VERSION "Reviewed Honda profile J35_6AT"

NS_ :

BS_:

BU_: EPS METER PCM UNKNOWN VSA

CM_ BO_ 57 "No saved selected registration; bus presence unproved; direction relative to PCM.";
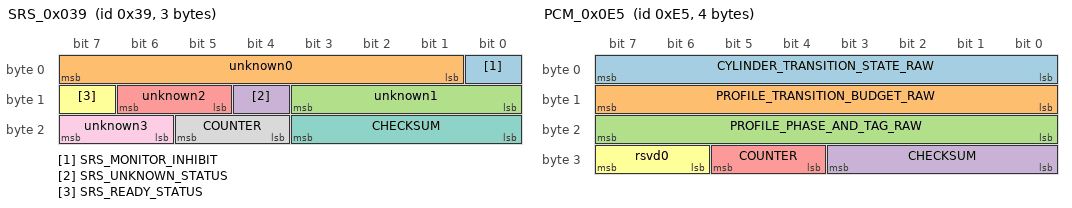
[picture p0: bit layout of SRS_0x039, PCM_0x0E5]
BO_ 57 SRS_0x039: 3 UNKNOWN
 SG_ SRS_MONITOR_INHIBIT : 0|1@1+ (1,0) [0|1] ""  PCM
 SG_ unknown0 : 1|7@1+ (1,0) [0|127] ""  PCM
 SG_ unknown1 : 8|4@1+ (1,0) [0|15] ""  PCM
 SG_ SRS_UNKNOWN_STATUS : 12|1@1+ (1,0) [0|1] ""  PCM
 SG_ unknown2 : 13|2@1+ (1,0) [0|3] ""  PCM
 SG_ SRS_READY_STATUS : 15|1@1+ (1,0) [0|1] ""  PCM
 SG_ CHECKSUM : 16|4@1+ (1,0) [0|15] ""  PCM
 SG_ COUNTER : 20|2@1+ (1,0) [0|3] ""  PCM
 SG_ unknown3 : 22|2@1+ (1,0) [0|3] ""  PCM

CM_ BO_ 145 "No saved selected registration; bus presence unproved; direction relative to PCM. Kinematics codes; X740 HDS associations are reference-only. Physical axes/scales and installed source remain qualified.";
BO_ 145 VSA_0x091: 8 VSA
 SG_ CRYAW2 : 7|10@0+ (1,0) [0|1023] "raw"  PCM
 SG_ AuxiliaryCode : 13|8@0+ (1,0) [0|255] ""  PCM
 SG_ CGLAT2 : 19|10@0+ (1,0) [0|1023] "raw"  PCM
 SG_ unknown0 : 20|2@1+ (1,0) [0|3] ""  PCM
 SG_ CGLON2 : 25|10@0+ (1,0) [0|1023] "raw"  PCM
 SG_ unknown1 : 40|4@1+ (1,0) [0|15] ""  PCM
 SG_ LongitudinalFaultSummary : 44|1@1+ (1,0) [0|1] ""  PCM
 SG_ LateralFaultSummary : 45|1@1+ (1,0) [0|1] ""  PCM
 SG_ MonitorSummary0 : 46|1@1+ (1,0) [0|1] ""  PCM
 SG_ YawFaultSummary : 47|1@1+ (1,0) [0|1] ""  PCM
 SG_ MonitorCondition2 : 48|1@1+ (1,0) [0|1] ""  PCM
 SG_ MonitorSummary1 : 49|1@1+ (1,0) [0|1] ""  PCM
 SG_ unknown2 : 50|2@1+ (1,0) [0|3] ""  PCM
 SG_ LongitudinalFaultCondition : 52|1@1+ (1,0) [0|1] ""  PCM
 SG_ LateralFaultCondition : 53|1@1+ (1,0) [0|1] ""  PCM
 SG_ MonitorCondition0 : 54|1@1+ (1,0) [0|1] ""  PCM
 SG_ YawFaultCondition : 55|1@1+ (1,0) [0|1] ""  PCM
 SG_ CHECKSUM : 56|4@1+ (1,0) [0|15] ""  PCM
 SG_ COUNTER : 60|2@1+ (1,0) [0|3] ""  PCM
 SG_ unknown3 : 62|1@1+ (1,0) [0|1] ""  PCM
 SG_ ScalarNotReady : 63|1@1+ (1,0) [0|1] ""  PCM

CM_ BO_ 229 "TX ACTIVE; DLC4; direction relative to PCM.";
BO_ 229 PCM_0x0E5: 4 PCM
 SG_ CYLINDER_TRANSITION_STATE_RAW : 0|8@1+ (1,0) [0|255] ""  UNKNOWN
 SG_ PROFILE_TRANSITION_BUDGET_RAW : 8|8@1+ (1,0) [0|255] ""  UNKNOWN
 SG_ PROFILE_PHASE_AND_TAG_RAW : 16|8@1+ (1,0) [0|255] ""  UNKNOWN
 SG_ CHECKSUM : 24|4@1+ (1,0) [0|15] ""  UNKNOWN
 SG_ COUNTER : 28|2@1+ (1,0) [0|3] ""  UNKNOWN
 SG_ rsvd0 : 30|2@1+ (1,0) [0|3] ""  UNKNOWN

CM_ BO_ 316 "TX ACTIVE; DLC8; direction relative to PCM. Signed modeled/requested torque codes; Nm scale unresolved.";
BO_ 316 PCM_0x13C: 8 PCM
 SG_ TORQUE_ESTIMATE : 7|16@0- (1,0) [-32768|32767] "raw"  UNKNOWN
 SG_ TORQUE_TARGET : 23|16@0- (1,0) [-32768|32767] "raw"  UNKNOWN
 SG_ APP : 32|8@1+ (0.39215686274509803,0) [0|100] "%"  UNKNOWN
 SG_ TORQUE_STATE : 40|2@1+ (1,0) [0|3] ""  UNKNOWN
 SG_ rsvd0 : 42|2@1+ (1,0) [0|3] ""  UNKNOWN
 SG_ rsvd1 : 44|1@1+ (1,0) [0|1] ""  UNKNOWN
 SG_ FRAME1AA_WINDOW_LATCH : 45|1@1+ (1,0) [0|1] ""  UNKNOWN
 SG_ START_PHASE_LATCH : 46|1@1+ (1,0) [0|1] ""  UNKNOWN
 SG_ DTC_STATUS7_LATCH : 47|1@1+ (1,0) [0|1] ""  UNKNOWN
 SG_ rsvd2 : 48|2@1+ (1,0) [0|3] ""  UNKNOWN
 SG_ CLEPBCC : 50|1@1+ (1,0) [0|1] ""  UNKNOWN
 SG_ CONTROL_GUARD_RAW : 51|1@1+ (1,0) [0|1] ""  UNKNOWN
 SG_ rsvd3 : 52|4@1+ (1,0) [0|15] ""  UNKNOWN
 SG_ CHECKSUM : 56|4@1+ (1,0) [0|15] ""  UNKNOWN
 SG_ COUNTER : 60|2@1+ (1,0) [0|3] ""  UNKNOWN
 SG_ rsvd4 : 62|1@1+ (1,0) [0|1] ""  UNKNOWN
 SG_ FRAME_1AA_INVALID_OR_FALLBACK_ST : 63|1@1+ (1,0) [0|1] ""  UNKNOWN

CM_ BO_ 342 "No saved selected registration; bus presence unproved; direction relative to PCM. Signed BE angle/rate codes; decoder uses -raw*0.1 deg and -raw deg/s. Orientation and installed source remain qualified.";
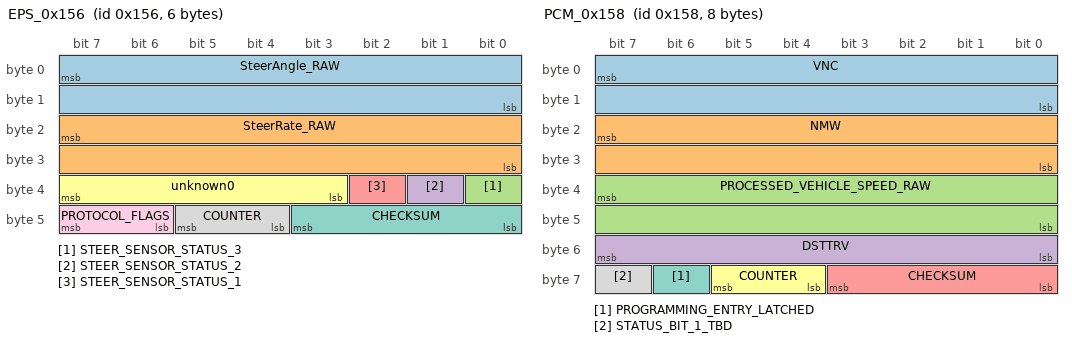
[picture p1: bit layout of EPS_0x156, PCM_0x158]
BO_ 342 EPS_0x156: 6 UNKNOWN
 SG_ SteerAngle_RAW : 7|16@0- (-0.1,0) [-3276.7000000000003|3276.8] "deg"  UNKNOWN
 SG_ SteerRate_RAW : 23|16@0- (-1,0) [-32767|32768] "deg/s"  UNKNOWN
 SG_ STEER_SENSOR_STATUS_3 : 32|1@1+ (1,0) [0|1] ""  UNKNOWN
 SG_ STEER_SENSOR_STATUS_2 : 33|1@1+ (1,0) [0|1] ""  UNKNOWN
 SG_ STEER_SENSOR_STATUS_1 : 34|1@1+ (1,0) [0|1] ""  UNKNOWN
 SG_ unknown0 : 35|5@1+ (1,0) [0|31] ""  UNKNOWN
 SG_ CHECKSUM : 40|4@1+ (1,0) [0|15] ""  UNKNOWN
 SG_ COUNTER : 44|2@1+ (1,0) [0|3] ""  UNKNOWN
 SG_ PROTOCOL_FLAGS : 46|2@1+ (1,0) [0|3] ""  UNKNOWN

CM_ BO_ 344 "TX ACTIVE; DLC8; direction relative to PCM.";
BO_ 344 PCM_0x158: 8 PCM
 SG_ VNC : 7|16@0+ (0.01,0) [0|655.35] ""  UNKNOWN
 SG_ NMW : 23|16@0+ (1,0) [0|65535] "raw"  UNKNOWN
 SG_ PROCESSED_VEHICLE_SPEED_RAW : 39|16@0+ (0.01,0) [0|655.35] ""  UNKNOWN
 SG_ DSTTRV : 48|8@1+ (1,0) [0|255] "raw"  UNKNOWN
 SG_ CHECKSUM : 56|4@1+ (1,0) [0|15] ""  UNKNOWN
 SG_ COUNTER : 60|2@1+ (1,0) [0|3] ""  UNKNOWN
 SG_ PROGRAMMING_ENTRY_LATCHED : 62|1@1+ (1,0) [0|1] ""  UNKNOWN
 SG_ STATUS_BIT_1_TBD : 63|1@1+ (1,0) [0|1] ""  UNKNOWN

CM_ BO_ 380 "TX ACTIVE; DLC8; direction relative to PCM.";
BO_ 380 PCM_0x17C: 8 PCM
 SG_ APP : 0|8@1+ (0.39215686274509803,0) [0|100] "%"  UNKNOWN
 SG_ THROTTLE_ABOVE_IDLE_CODE : 8|8@1+ (0.4,0) [0|102] "deg"  UNKNOWN
 SG_ NE : 23|16@0+ (1,0) [0|65535] "rpm"  UNKNOWN
 SG_ BKSW : 32|1@1+ (1,0) [0|1] ""  UNKNOWN
 SG_ CRUISE_CANCEL_EVENT : 33|1@1+ (1,0) [0|1] ""  UNKNOWN
 SG_ CRUISE_FAULT_SPEED_INHIBIT : 34|1@1+ (1,0) [0|1] ""  UNKNOWN
 SG_ CRUISE_ENGAGED : 35|1@1+ (1,0) [0|1] ""  UNKNOWN
 SG_ WARN : 36|1@1+ (1,0) [0|1] ""  UNKNOWN
 SG_ MILSTAT : 37|1@1+ (1,0) [0|1] ""  UNKNOWN
 SG_ CRPL : 38|1@1+ (1,0) [0|1] ""  UNKNOWN
 SG_ GAS_PEDAL_PRESSED : 39|1@1+ (1,0) [0|1] ""  UNKNOWN
 SG_ rsvd0 : 40|2@1+ (1,0) [0|3] ""  UNKNOWN
 SG_ ACCEL_PEDAL_FAULT : 42|1@1+ (1,0) [0|1] ""  UNKNOWN
 SG_ rsvd1 : 43|5@1+ (1,0) [0|31] ""  UNKNOWN
 SG_ rsvd2 : 48|5@1+ (1,0) [0|31] ""  UNKNOWN
 SG_ BKSWNC : 53|1@1+ (1,0) [0|1] ""  UNKNOWN
 SG_ CRUISE_TRANS_REQUEST_WIRE : 54|2@1+ (1,0) [0|3] ""  UNKNOWN
 SG_ CHECKSUM : 56|4@1+ (1,0) [0|15] ""  UNKNOWN
 SG_ COUNTER : 60|2@1+ (1,0) [0|3] ""  UNKNOWN
 SG_ rsvd3 : 62|1@1+ (1,0) [0|1] ""  UNKNOWN
 SG_ DTC_GROUP_WARNING_REQUESTED : 63|1@1+ (1,0) [0|1] ""  UNKNOWN

CM_ BO_ 392 "TX ACTIVE; DLC6; direction relative to PCM.";
BO_ 392 PCM_0x188: 6 PCM
 SG_ SHIFT_CONTROL_CODE_A_RAW : 0|4@1+ (1,0) [0|15] ""  UNKNOWN
 SG_ TRANSMISSION_LATCH_RAW : 4|1@1+ (1,0) [0|1] ""  UNKNOWN
 SG_ CONDITIONED_GEAR_CODE_RAW : 5|3@1+ (1,0) [0|7] ""  UNKNOWN
 SG_ SHIFT_CONTROL_CODE_B_RAW : 8|3@1+ (1,0) [0|7] ""  UNKNOWN
 SG_ LEDC : 11|1@1+ (1,0) [0|1] ""  UNKNOWN
 SG_ LEDB : 12|1@1+ (1,0) [0|1] ""  UNKNOWN
 SG_ LEDA : 13|1@1+ (1,0) [0|1] ""  UNKNOWN
 SG_ SIGNED_CODE_SPILL_D1_RAW : 14|2@1+ (1,0) [0|3] ""  UNKNOWN
 SG_ SELECTOR_INDICATOR_RAW : 16|1@1+ (1,0) [0|1] ""  UNKNOWN
 SG_ TRANSMISSION_STATE_RAW : 17|1@1+ (1,0) [0|1] ""  UNKNOWN
 SG_ TRANSMISSION_QUALIFICATION_RAW : 18|1@1+ (1,0) [0|1] ""  UNKNOWN
 SG_ MIND : 19|1@1+ (1,0) [0|1] ""  UNKNOWN
 SG_ INDICATOR_FAULT_RAW : 20|1@1+ (1,0) [0|1] ""  UNKNOWN
 SG_ TRANSMISSION_DIAGNOSTIC_LATCH_RA : 21|1@1+ (1,0) [0|1] ""  UNKNOWN
 SG_ COMMUNICATION_STATUS_RAW : 22|1@1+ (1,0) [0|1] ""  UNKNOWN
 SG_ SHIFT_INDICATOR_CONTROL_RAW : 23|1@1+ (1,0) [0|1] ""  UNKNOWN
 SG_ ATPP : 24|1@1+ (1,0) [0|1] ""  UNKNOWN
 SG_ ATPR : 25|1@1+ (1,0) [0|1] ""  UNKNOWN
 SG_ ATPN : 26|1@1+ (1,0) [0|1] ""  UNKNOWN
 SG_ ATPD : 27|1@1+ (1,0) [0|1] ""  UNKNOWN
 SG_ rsvd0 : 28|1@1+ (1,0) [0|1] ""  UNKNOWN
 SG_ ATPD3 : 29|1@1+ (1,0) [0|1] ""  UNKNOWN
 SG_ ATP2_OR_ATPL : 30|1@1+ (1,0) [0|1] ""  UNKNOWN
 SG_ ATP1 : 31|1@1+ (1,0) [0|1] ""  UNKNOWN
 SG_ SHIFT_POSITION_DISPLAY_CODE_RAW : 32|4@1+ (1,0) [0|15] ""  UNKNOWN
 SG_ ATPS : 36|1@1+ (1,0) [0|1] ""  UNKNOWN
 SG_ SERVICE_RESET_ACK_RAW : 37|1@1+ (1,0) [0|1] ""  UNKNOWN
 SG_ SERVICE_DUE_RAW : 38|1@1+ (1,0) [0|1] ""  UNKNOWN
 SG_ SIGNED_CODE_SPILL_D4_RAW : 39|1@1+ (1,0) [0|1] ""  UNKNOWN
 SG_ CHECKSUM : 40|4@1+ (1,0) [0|15] ""  UNKNOWN
 SG_ COUNTER : 44|2@1+ (1,0) [0|3] ""  UNKNOWN
 SG_ QUALIFIED_TRANSMISSION_STATUS_RA : 46|1@1+ (1,0) [0|1] ""  UNKNOWN
 SG_ rsvd1 : 47|1@1+ (1,0) [0|1] ""  UNKNOWN

CM_ BO_ 398 "RX ACTIVE; DLC3; direction relative to PCM. EPS-current diagnostic view is gated and nonlinear; ordinary wire value stays raw.";
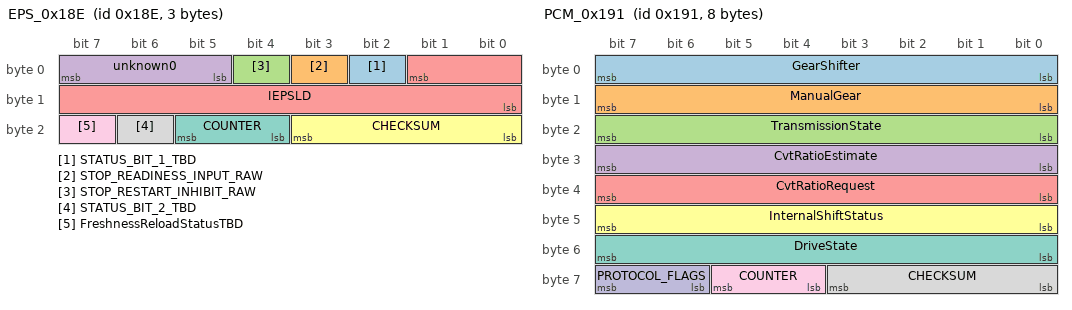
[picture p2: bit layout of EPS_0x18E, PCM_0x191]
BO_ 398 EPS_0x18E: 3 EPS
 SG_ STATUS_BIT_1_TBD : 2|1@1+ (1,0) [0|1] ""  PCM
 SG_ STOP_READINESS_INPUT_RAW : 3|1@1+ (1,0) [0|1] ""  PCM
 SG_ STOP_RESTART_INHIBIT_RAW : 4|1@1+ (1,0) [0|1] ""  PCM
 SG_ unknown0 : 5|3@1+ (1,0) [0|7] ""  PCM
 SG_ IEPSLD : 1|10@0+ (1,0) [0|1023] "raw"  PCM
 SG_ CHECKSUM : 16|4@1+ (1,0) [0|15] ""  PCM
 SG_ COUNTER : 20|2@1+ (1,0) [0|3] ""  PCM
 SG_ STATUS_BIT_2_TBD : 22|1@1+ (1,0) [0|1] ""  PCM
 SG_ FreshnessReloadStatusTBD : 23|1@1+ (1,0) [0|1] ""  PCM

CM_ BO_ 401 "No saved selected registration; bus presence unproved; direction relative to PCM.Legacy opaque template; no selected J35 0x191 registration or transferred CVT meanings.";
BO_ 401 PCM_0x191: 8 PCM
 SG_ GearShifter : 0|8@1+ (1,0) [0|255] ""  UNKNOWN
 SG_ ManualGear : 8|8@1+ (1,0) [0|255] ""  UNKNOWN
 SG_ TransmissionState : 16|8@1+ (1,0) [0|255] ""  UNKNOWN
 SG_ CvtRatioEstimate : 24|8@1+ (1,0) [0|255] ""  UNKNOWN
 SG_ CvtRatioRequest : 32|8@1+ (1,0) [0|255] ""  UNKNOWN
 SG_ InternalShiftStatus : 40|8@1+ (1,0) [0|255] ""  UNKNOWN
 SG_ DriveState : 48|8@1+ (1,0) [0|255] ""  UNKNOWN
 SG_ CHECKSUM : 56|4@1+ (1,0) [0|15] ""  UNKNOWN
 SG_ COUNTER : 60|2@1+ (1,0) [0|3] ""  UNKNOWN
 SG_ PROTOCOL_FLAGS : 62|2@1+ (1,0) [0|3] ""  UNKNOWN

CM_ BO_ 411 "No saved selected registration; bus presence unproved; direction relative to PCM.";
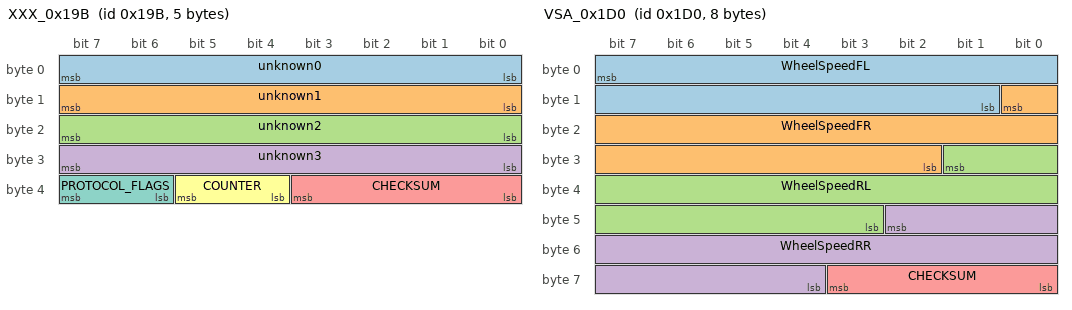
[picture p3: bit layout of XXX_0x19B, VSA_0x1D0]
BO_ 411 XXX_0x19B: 5 UNKNOWN
 SG_ unknown0 : 0|8@1+ (1,0) [0|255] ""  UNKNOWN
 SG_ unknown1 : 8|8@1+ (1,0) [0|255] ""  UNKNOWN
 SG_ unknown2 : 16|8@1+ (1,0) [0|255] ""  UNKNOWN
 SG_ unknown3 : 24|8@1+ (1,0) [0|255] ""  UNKNOWN
 SG_ CHECKSUM : 32|4@1+ (1,0) [0|15] ""  UNKNOWN
 SG_ COUNTER : 36|2@1+ (1,0) [0|3] ""  UNKNOWN
 SG_ PROTOCOL_FLAGS : 38|2@1+ (1,0) [0|3] ""  UNKNOWN

CM_ BO_ 420 "RX ACTIVE; DLC8; direction relative to PCM. Master-cylinder pressure code precedes learned-zero correction. kPa association is L640-only; see ExactConversion.";
BO_ 420 VSA_0x1A4: 8 VSA
 SG_ MASTER_CYLINDER_PRESSURE_RAW : 3|12@0+ (1,0) [0|4095] "raw"  PCM
 SG_ PRESSURE_RELATED_INHIBIT_1 : 4|1@1+ (1,0) [0|1] ""  PCM
 SG_ PRESSURE_RELATED_INHIBIT_2 : 5|1@1+ (1,0) [0|1] ""  PCM
 SG_ unknown0 : 6|2@1+ (1,0) [0|3] ""  PCM
 SG_ VSA_INTERVENTION_ACTIVE : 16|1@1+ (1,0) [0|1] ""  PCM
 SG_ ABS_INTERVENTION_ACTIVE : 17|1@1+ (1,0) [0|1] ""  PCM
 SG_ STATUS_BIT_1_TBD : 18|1@1+ (1,0) [0|1] ""  PCM
 SG_ STATUS_BIT_2_TBD : 19|1@1+ (1,0) [0|1] ""  PCM
 SG_ VSACASEN : 20|1@1+ (1,0) [0|1] ""  PCM
 SG_ STATUS_BIT_3_TBD : 21|1@1+ (1,0) [0|1] ""  PCM
 SG_ unknown2 : 22|1@1+ (1,0) [0|1] ""  PCM
 SG_ COMPUTER_BRAKING_TBD : 23|1@1+ (1,0) [0|1] ""  PCM
 SG_ unknown3 : 24|4@1+ (1,0) [0|15] ""  PCM
 SG_ VSA_DISABLED_TBD : 28|1@1+ (1,0) [0|1] ""  PCM
 SG_ unknown4 : 29|1@1+ (1,0) [0|1] ""  PCM
 SG_ VSA_SYSTEM_UNAVAILABLE_TBD : 30|1@1+ (1,0) [0|1] ""  PCM
 SG_ unknown5 : 31|1@1+ (1,0) [0|1] ""  PCM
 SG_ unknown6 : 32|2@1+ (1,0) [0|3] ""  PCM
 SG_ VSA_WATCHDOG_REFRESH_REQUEST : 34|1@1+ (1,0) [0|1] ""  PCM
 SG_ unknown7 : 35|5@1+ (1,0) [0|31] ""  PCM
 SG_ unknown8 : 40|4@1+ (1,0) [0|15] ""  PCM
 SG_ IDLE_STOP_BRAKE_TRANSITION_TBD : 44|1@1+ (1,0) [0|1] ""  PCM
 SG_ unknown9 : 45|3@1+ (1,0) [0|7] ""  PCM
 SG_ unknown10 : 48|4@1+ (1,0) [0|15] ""  PCM
 SG_ BRAKE_HOLD_RELATED_TBD : 52|1@1+ (1,0) [0|1] ""  PCM
 SG_ unknown11 : 53|1@1+ (1,0) [0|1] ""  PCM
 SG_ STATUS_BIT_4_TBD : 54|1@1+ (1,0) [0|1] ""  PCM
 SG_ unknown12 : 55|1@1+ (1,0) [0|1] ""  PCM
 SG_ CHECKSUM : 56|4@1+ (1,0) [0|15] ""  PCM
 SG_ COUNTER : 60|2@1+ (1,0) [0|3] ""  PCM
 SG_ STATUS_BIT_5_TBD : 62|1@1+ (1,0) [0|1] ""  PCM
 SG_ STATUS_BIT_6_TBD : 63|1@1+ (1,0) [0|1] ""  PCM

CM_ BO_ 422 "RX ACTIVE; DLC8; direction relative to PCM.";
BO_ 422 SCM_0x1A6: 8 METER
 SG_ HEADLIGHT_STATE : 0|2@1+ (1,0) [0|3] ""  PCM
 SG_ LIGHTING_STATUS_TBD : 2|1@1+ (1,0) [0|1] ""  PCM
 SG_ unknown0 : 3|1@1+ (1,0) [0|1] ""  PCM
 SG_ CruiseControlButtons : 4|4@1+ (1,0) [0|15] ""  PCM
 SG_ unknown1 : 8|4@1+ (1,0) [0|15] ""  PCM
 SG_ STATUS_BIT_1_TBD : 12|2@1+ (1,0) [0|3] ""  PCM
 SG_ unknown2 : 14|2@1+ (1,0) [0|3] ""  PCM
 SG_ unknown3 : 16|4@1+ (1,0) [0|15] ""  PCM
 SG_ AcCompressorOn : 20|1@1+ (1,0) [0|1] ""  PCM
 SG_ unknown4 : 21|1@1+ (1,0) [0|1] ""  PCM
 SG_ STATUS_BIT_2_TBD : 22|1@1+ (1,0) [0|1] ""  PCM
 SG_ unknown5 : 23|1@1+ (1,0) [0|1] ""  PCM
 SG_ FuelLevel : 24|8@1+ (1,0) [0|255] ""  PCM
 SG_ FUEL_LEVEL_PCM_COUNTS_RAW : 32|8@1+ (4,0) [0|1020] "receiver count"  PCM
 SG_ SCM_STATUS_BIT_TBD : 40|1@1+ (1,0) [0|1] ""  PCM
 SG_ unknown6 : 41|1@1+ (1,0) [0|1] ""  PCM
 SG_ CRUISE_SETTING_STATE_TBD : 42|3@1+ (1,0) [0|7] ""  PCM
 SG_ SCM_STATUS_CODE_TBD : 45|2@1+ (1,0) [0|3] ""  PCM
 SG_ OUT_WARN_CRUMAIN : 47|1@1+ (1,0) [0|1] ""  PCM
 SG_ unknown7 : 48|8@1+ (1,0) [0|255] ""  PCM
 SG_ CHECKSUM : 56|4@1+ (1,0) [0|15] ""  PCM
 SG_ COUNTER : 60|2@1+ (1,0) [0|3] ""  PCM
 SG_ STATUS_BIT_3_TBD : 62|1@1+ (1,0) [0|1] ""  PCM
 SG_ unknown8 : 63|1@1+ (1,0) [0|1] ""  PCM

CM_ BO_ 426 "RX ACTIVE; DLC8; direction relative to PCM.";
BO_ 426 XXX_0x1AA: 8 VSA
 SG_ SignedNumericChannelTBD : 7|16@0- (1,0) [-32768|32767] "raw"  PCM
 SG_ StateCodeD2Bits1To0TBD : 16|2@1+ (1,0) [0|3] ""  PCM
 SG_ StateCodeD2Bits3To2TBD : 18|2@1+ (1,0) [0|3] ""  PCM
 SG_ VsaCategoryStateTBD : 20|4@1+ (1,0) [0|15] ""  PCM
 SG_ unknown0 : 24|3@1+ (1,0) [0|7] ""  PCM
 SG_ STATUS_BIT_1_TBD : 27|1@1+ (1,0) [0|1] ""  PCM
 SG_ unknown1 : 28|4@1+ (1,0) [0|15] ""  PCM
 SG_ unknown2 : 32|8@1+ (1,0) [0|255] ""  PCM
 SG_ unknown3 : 40|2@1+ (1,0) [0|3] ""  PCM
 SG_ STATUS_BIT_2_TBD : 42|1@1+ (1,0) [0|1] ""  PCM
 SG_ STATUS_BIT_3_TBD : 43|1@1+ (1,0) [0|1] ""  PCM
 SG_ unknown4 : 44|2@1+ (1,0) [0|3] ""  PCM
 SG_ STATUS_BIT_4_TBD : 46|1@1+ (1,0) [0|1] ""  PCM
 SG_ STATUS_BIT_5_TBD : 47|1@1+ (1,0) [0|1] ""  PCM
 SG_ unknown5 : 48|8@1+ (1,0) [0|255] ""  PCM
 SG_ CHECKSUM : 56|4@1+ (1,0) [0|15] ""  PCM
 SG_ COUNTER : 60|2@1+ (1,0) [0|3] ""  PCM
 SG_ STATUS_BIT_6_TBD : 62|1@1+ (1,0) [0|1] ""  PCM
 SG_ unknown6 : 63|1@1+ (1,0) [0|1] ""  PCM

CM_ BO_ 432 "No saved selected registration; bus presence unproved; direction relative to PCM. Standstill/status slices retain saved L640 coordinates; J35 consumption and physical meanings remain qualified.";
BO_ 432 VSA_0x1B0: 7 VSA
 SG_ unknown0 : 0|8@1+ (1,0) [0|255] ""  PCM
 SG_ unknown1 : 8|4@1+ (1,0) [0|15] ""  PCM
 SG_ WHEELS_MOVING : 12|1@1+ (1,0) [0|1] ""  PCM
 SG_ unknown2 : 13|2@1+ (1,0) [0|3] ""  PCM
 SG_ unknown3 : 15|1@1+ (1,0) [0|1] ""  PCM
 SG_ unknown4 : 16|8@1+ (1,0) [0|255] ""  PCM
 SG_ unknown5 : 24|8@1+ (1,0) [0|255] ""  PCM
 SG_ CHECKSUM : 48|4@1+ (1,0) [0|15] ""  PCM
 SG_ COUNTER : 52|2@1+ (1,0) [0|3] ""  PCM
 SG_ PROTOCOL_FLAGS : 54|2@1+ (1,0) [0|3] ""  PCM
 SG_ STANDSTILL_BRAKE_STATUS_D4B3_TBD : 35|1@1+ (1,0) [0|0] ""  PCM
 SG_ unknown6 : 32|3@1+ (1,0) [0|0] ""  PCM
 SG_ STANDSTILL_BRAKE_STATUS_D4B4_TBD : 36|1@1+ (1,0) [0|0] ""  PCM
 SG_ STANDSTILL_BRAKE_STATUS_D4B5_TBD : 37|1@1+ (1,0) [0|0] ""  PCM
 SG_ STANDSTILL_BRAKE_STATUS_D4B6_TBD : 38|1@1+ (1,0) [0|0] ""  PCM
 SG_ unknown6_part1 : 39|1@1+ (1,0) [0|0] ""  PCM
 SG_ STANDSTILL_STATUS_D5B0_TBD : 40|1@1+ (1,0) [0|0] ""  PCM
 SG_ STANDSTILL_STATUS_D5B1_TBD : 41|1@1+ (1,0) [0|0] ""  PCM
 SG_ STANDSTILL_STATE_D5_BITS3_2_TBD : 42|2@1+ (1,0) [0|0] ""  PCM
 SG_ unknown7 : 44|4@1+ (1,0) [0|0] ""  PCM

CM_ BO_ 464 "RX ACTIVE; DLC8; direction relative to PCM. Four packed unsigned 15-bit wheel codes; 0.00993422 km/h/count corroborated. No rolling counter.";
BO_ 464 VSA_0x1D0: 8 VSA
 SG_ WheelSpeedFL : 7|15@0+ (0.00993422,0) [0|325.51458674] "km/h"  PCM
 SG_ WheelSpeedFR : 8|15@0+ (0.00993422,0) [0|325.51458674] "km/h"  PCM
 SG_ WheelSpeedRL : 25|15@0+ (0.00993422,0) [0|325.51458674] "km/h"  PCM
 SG_ WheelSpeedRR : 42|15@0+ (0.00993422,0) [0|325.51458674] "km/h"  PCM
 SG_ CHECKSUM : 56|4@1+ (1,0) [0|15] ""  PCM

CM_ BO_ 476 "TX ACTIVE; DLC4; direction relative to PCM.";
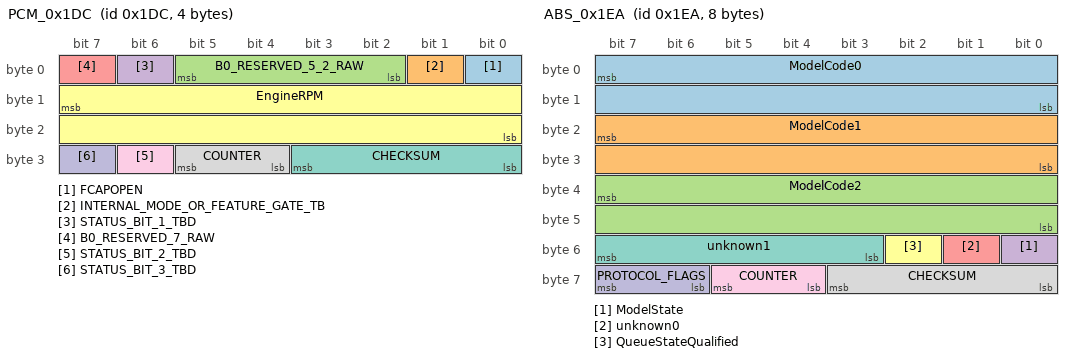
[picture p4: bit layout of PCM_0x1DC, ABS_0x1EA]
BO_ 476 PCM_0x1DC: 4 PCM
 SG_ FCAPOPEN : 0|1@1+ (1,0) [0|1] ""  UNKNOWN
 SG_ INTERNAL_MODE_OR_FEATURE_GATE_TB : 1|1@1+ (1,0) [0|1] ""  UNKNOWN
 SG_ B0_RESERVED_5_2_RAW : 2|4@1+ (1,0) [0|15] ""  UNKNOWN
 SG_ STATUS_BIT_1_TBD : 6|1@1+ (1,0) [0|1] ""  UNKNOWN
 SG_ B0_RESERVED_7_RAW : 7|1@1+ (1,0) [0|1] ""  UNKNOWN
 SG_ EngineRPM : 15|16@0+ (1,0) [0|65535] "rpm"  UNKNOWN
 SG_ CHECKSUM : 24|4@1+ (1,0) [0|15] ""  UNKNOWN
 SG_ COUNTER : 28|2@1+ (1,0) [0|3] ""  UNKNOWN
 SG_ STATUS_BIT_2_TBD : 30|1@1+ (1,0) [0|1] ""  UNKNOWN
 SG_ STATUS_BIT_3_TBD : 31|1@1+ (1,0) [0|1] ""  UNKNOWN

CM_ BO_ 490 "No saved selected registration; bus presence unproved; direction relative to PCM. Model-output words; acceleration units remain unproved.";
BO_ 490 ABS_0x1EA: 8 VSA
 SG_ ModelCode0 : 7|16@0+ (1,0) [0|65535] "raw"  UNKNOWN
 SG_ ModelCode1 : 23|16@0+ (1,0) [0|65535] "raw"  UNKNOWN
 SG_ ModelCode2 : 39|16@0+ (1,0) [0|65535] "raw"  UNKNOWN
 SG_ ModelState : 48|1@1+ (1,0) [0|1] ""  UNKNOWN
 SG_ unknown0 : 49|1@1+ (1,0) [0|1] ""  UNKNOWN
 SG_ QueueStateQualified : 50|1@1+ (1,0) [0|1] ""  UNKNOWN
 SG_ unknown1 : 51|5@1+ (1,0) [0|31] ""  UNKNOWN
 SG_ CHECKSUM : 56|4@1+ (1,0) [0|15] ""  UNKNOWN
 SG_ COUNTER : 60|2@1+ (1,0) [0|3] ""  UNKNOWN
 SG_ PROTOCOL_FLAGS : 62|2@1+ (1,0) [0|3] ""  UNKNOWN

CM_ BO_ 493 "TX ACTIVE; DLC3; direction relative to PCM.";
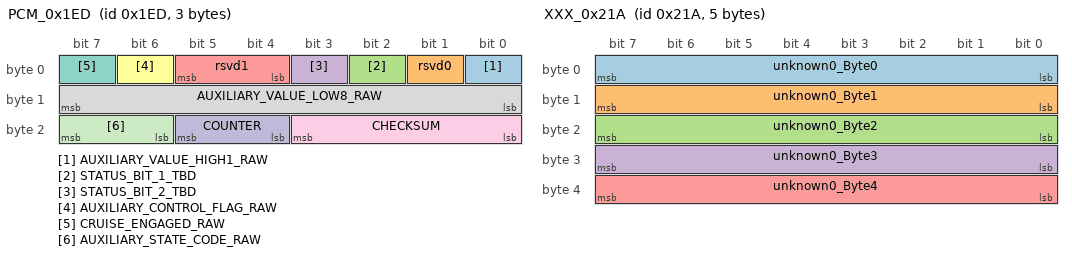
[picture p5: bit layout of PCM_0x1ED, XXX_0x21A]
BO_ 493 PCM_0x1ED: 3 PCM
 SG_ AUXILIARY_VALUE_HIGH1_RAW : 0|1@1+ (1,0) [0|1] ""  UNKNOWN
 SG_ rsvd0 : 1|1@1+ (1,0) [0|1] ""  UNKNOWN
 SG_ STATUS_BIT_1_TBD : 2|1@1+ (1,0) [0|1] ""  UNKNOWN
 SG_ STATUS_BIT_2_TBD : 3|1@1+ (1,0) [0|1] ""  UNKNOWN
 SG_ rsvd1 : 4|2@1+ (1,0) [0|3] ""  UNKNOWN
 SG_ AUXILIARY_CONTROL_FLAG_RAW : 6|1@1+ (1,0) [0|1] ""  UNKNOWN
 SG_ CRUISE_ENGAGED_RAW : 7|1@1+ (1,0) [0|1] ""  UNKNOWN
 SG_ AUXILIARY_VALUE_LOW8_RAW : 8|8@1+ (1,0) [0|255] ""  UNKNOWN
 SG_ CHECKSUM : 16|4@1+ (1,0) [0|15] ""  UNKNOWN
 SG_ COUNTER : 20|2@1+ (1,0) [0|3] ""  UNKNOWN
 SG_ AUXILIARY_STATE_CODE_RAW : 22|2@1+ (1,0) [0|3] ""  UNKNOWN

CM_ BO_ 538 "No saved selected registration; bus presence unproved; direction relative to PCM.";
BO_ 538 XXX_0x21A: 5 VSA
 SG_ unknown0_Byte0 : 0|8@1+ (1,0) [0|255] ""  PCM
 SG_ unknown0_Byte1 : 8|8@1+ (1,0) [0|255] ""  PCM
 SG_ unknown0_Byte2 : 16|8@1+ (1,0) [0|255] ""  PCM
 SG_ unknown0_Byte3 : 24|8@1+ (1,0) [0|255] ""  PCM
 SG_ unknown0_Byte4 : 32|8@1+ (1,0) [0|255] ""  PCM

CM_ BO_ 542 "No saved selected registration; bus presence unproved; direction relative to PCM.";
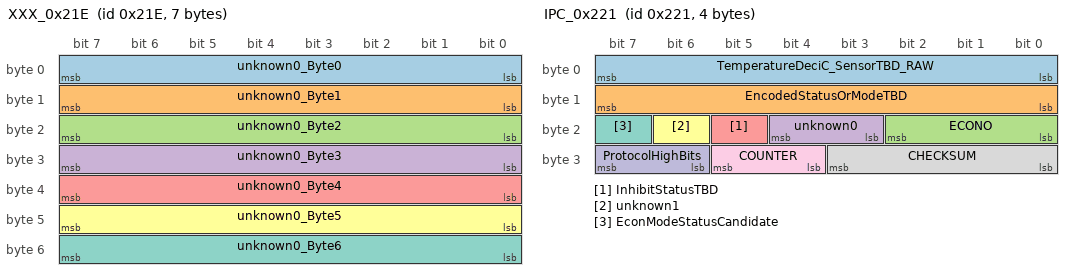
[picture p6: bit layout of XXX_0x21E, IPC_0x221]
BO_ 542 XXX_0x21E: 7 METER
 SG_ unknown0_Byte0 : 0|8@1+ (1,0) [0|255] ""  PCM
 SG_ unknown0_Byte1 : 8|8@1+ (1,0) [0|255] ""  PCM
 SG_ unknown0_Byte2 : 16|8@1+ (1,0) [0|255] ""  PCM
 SG_ unknown0_Byte3 : 24|8@1+ (10,-400) [-400|2150] "internal count"  PCM
 SG_ unknown0_Byte4 : 32|8@1+ (1,0) [0|255] ""  PCM
 SG_ unknown0_Byte5 : 40|8@1+ (1,0) [0|255] ""  PCM
 SG_ unknown0_Byte6 : 48|8@1+ (1,0) [0|255] ""  PCM

CM_ BO_ 545 "RX ACTIVE; DLC4; direction relative to PCM.";
BO_ 545 IPC_0x221: 4 UNKNOWN
 SG_ TemperatureDeciC_SensorTBD_RAW : 0|8@1+ (1,-30) [-30|225] "degC"  PCM
 SG_ EncodedStatusOrModeTBD : 8|8@1+ (1,0) [0|255] ""  PCM
 SG_ ECONO : 16|3@1+ (1,0) [0|7] ""  PCM
 SG_ unknown0 : 19|2@1+ (1,0) [0|3] ""  PCM
 SG_ InhibitStatusTBD : 21|1@1+ (1,0) [0|1] ""  PCM
 SG_ unknown1 : 22|1@1+ (1,0) [0|1] ""  PCM
 SG_ EconModeStatusCandidate : 23|1@1+ (1,0) [0|1] ""  PCM
 SG_ CHECKSUM : 24|4@1+ (1,0) [0|15] ""  PCM
 SG_ COUNTER : 28|2@1+ (1,0) [0|3] ""  PCM
 SG_ ProtocolHighBits : 30|2@1+ (1,0) [0|3] ""  PCM

CM_ BO_ 597 "No saved selected registration; bus presence unproved; direction relative to PCM. Byte6 U8 sequence; byte7 additive U8 checksum. FA/FF and status/fallback paths are not unconditional physical speeds.";
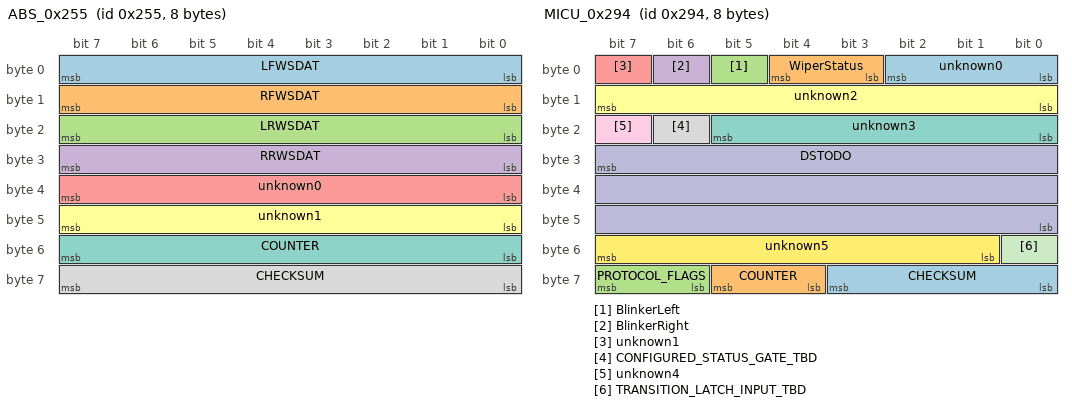
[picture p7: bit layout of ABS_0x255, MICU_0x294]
BO_ 597 ABS_0x255: 8 VSA
 SG_ LFWSDAT : 0|8@1+ (1,0) [0|255] "raw"  UNKNOWN
 SG_ RFWSDAT : 8|8@1+ (1,0) [0|255] "raw"  UNKNOWN
 SG_ LRWSDAT : 16|8@1+ (1,0) [0|255] "raw"  UNKNOWN
 SG_ RRWSDAT : 24|8@1+ (1,0) [0|255] "raw"  UNKNOWN
 SG_ unknown0 : 32|8@1+ (1,0) [0|255] ""  UNKNOWN
 SG_ unknown1 : 40|8@1+ (1,0) [0|255] ""  UNKNOWN
 SG_ COUNTER : 48|8@1+ (1,0) [0|255] ""  UNKNOWN
 SG_ CHECKSUM : 56|8@1+ (1,0) [0|255] ""  UNKNOWN

CM_ BO_ 660 "RX ACTIVE; DLC8; direction relative to PCM.";
BO_ 660 MICU_0x294: 8 METER
 SG_ unknown0 : 0|3@1+ (1,0) [0|7] ""  PCM
 SG_ WiperStatus : 3|2@1+ (1,0) [0|3] ""  PCM
 SG_ BlinkerLeft : 5|1@1+ (1,0) [0|1] ""  PCM
 SG_ BlinkerRight : 6|1@1+ (1,0) [0|1] ""  PCM
 SG_ unknown1 : 7|1@1+ (1,0) [0|1] ""  PCM
 SG_ unknown2 : 8|8@1+ (1,0) [0|255] ""  PCM
 SG_ unknown3 : 16|6@1+ (1,0) [0|63] ""  PCM
 SG_ CONFIGURED_STATUS_GATE_TBD : 22|1@1+ (1,0) [0|1] ""  PCM
 SG_ unknown4 : 23|1@1+ (1,0) [0|1] ""  PCM
 SG_ DSTODO : 31|24@0+ (1,0) [0|16777215] "raw"  PCM
 SG_ TRANSITION_LATCH_INPUT_TBD : 48|1@1+ (1,0) [0|1] ""  PCM
 SG_ unknown5 : 49|7@1+ (1,0) [0|127] ""  PCM
 SG_ CHECKSUM : 56|4@1+ (1,0) [0|15] ""  PCM
 SG_ COUNTER : 60|2@1+ (1,0) [0|3] ""  PCM
 SG_ PROTOCOL_FLAGS : 62|2@1+ (1,0) [0|3] ""  PCM

CM_ BO_ 661 "No saved selected registration; bus presence unproved; direction relative to PCM. Wire DLC4; source header retains a two-byte documentary prefix. Other-profile source/fitment remains qualified.";
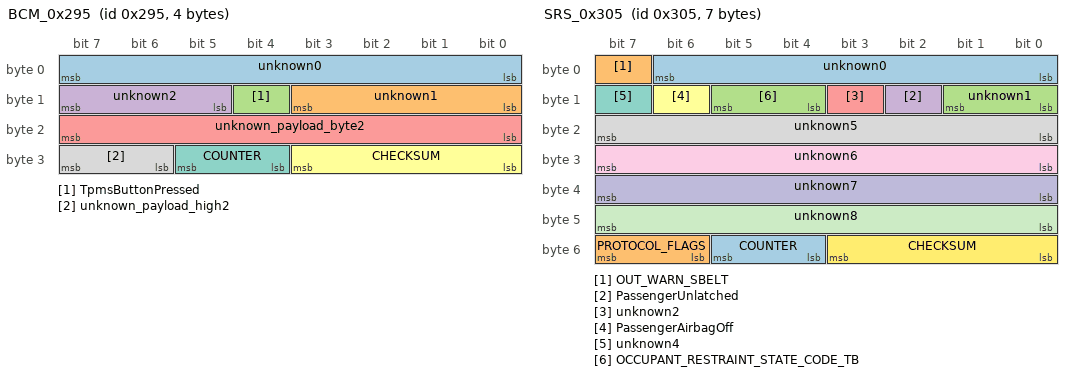
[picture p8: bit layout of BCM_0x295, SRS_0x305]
BO_ 661 BCM_0x295: 4 UNKNOWN
 SG_ unknown0 : 0|8@1+ (1,0) [0|255] ""  UNKNOWN
 SG_ unknown1 : 8|4@1+ (1,0) [0|15] ""  UNKNOWN
 SG_ TpmsButtonPressed : 12|1@1+ (1,0) [0|1] ""  UNKNOWN
 SG_ unknown2 : 13|3@1+ (1,0) [0|7] ""  UNKNOWN
 SG_ unknown_payload_byte2 : 16|8@1+ (1,0) [0|255] ""  UNKNOWN
 SG_ CHECKSUM : 24|4@1+ (1,0) [0|15] ""  UNKNOWN
 SG_ COUNTER : 28|2@1+ (1,0) [0|3] ""  UNKNOWN
 SG_ unknown_payload_high2 : 30|2@1+ (1,0) [0|3] ""  UNKNOWN

CM_ BO_ 773 "No saved selected registration; bus presence unproved; direction relative to PCM. d1[5:4] is a two-bit restraint-state code; individual buckle meanings remain unresolved.";
BO_ 773 SRS_0x305: 7 UNKNOWN
 SG_ unknown0 : 0|7@1+ (1,0) [0|127] ""  PCM
 SG_ OUT_WARN_SBELT : 7|1@1+ (1,0) [0|1] ""  PCM
 SG_ unknown1 : 8|2@1+ (1,0) [0|3] ""  PCM
 SG_ PassengerUnlatched : 10|1@1+ (1,0) [0|1] ""  PCM
 SG_ unknown2 : 11|1@1+ (1,0) [0|1] ""  PCM
 SG_ PassengerAirbagOff : 14|1@1+ (1,0) [0|1] ""  PCM
 SG_ unknown4 : 15|1@1+ (1,0) [0|1] ""  PCM
 SG_ unknown5 : 16|8@1+ (1,0) [0|255] ""  PCM
 SG_ unknown6 : 24|8@1+ (1,0) [0|255] ""  PCM
 SG_ unknown7 : 32|8@1+ (1,0) [0|255] ""  PCM
 SG_ unknown8 : 40|8@1+ (1,0) [0|255] ""  PCM
 SG_ CHECKSUM : 48|4@1+ (1,0) [0|15] ""  PCM
 SG_ COUNTER : 52|2@1+ (1,0) [0|3] ""  PCM
 SG_ PROTOCOL_FLAGS : 54|2@1+ (1,0) [0|3] ""  PCM
 SG_ OCCUPANT_RESTRAINT_STATE_CODE_TB : 12|2@1+ (1,0) [0|0] ""  PCM

CM_ BO_ 777 "RX ACTIVE; DLC8; direction relative to PCM.";
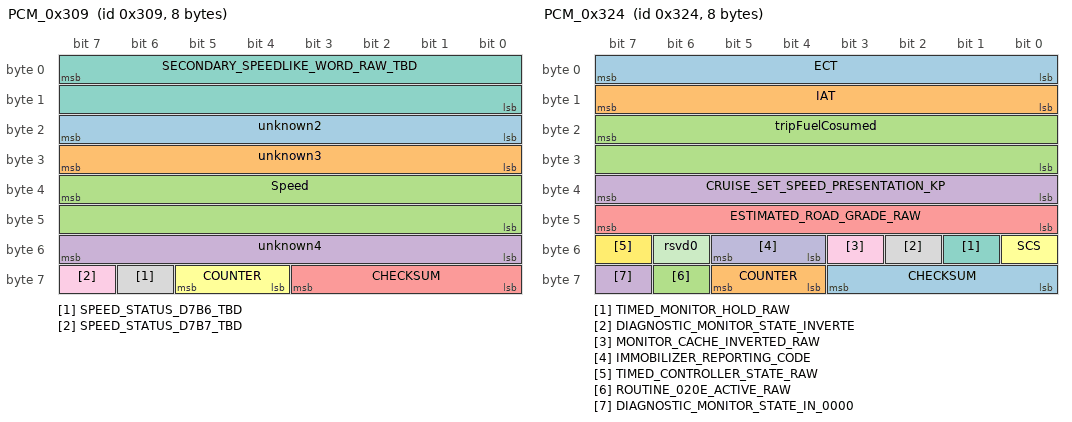
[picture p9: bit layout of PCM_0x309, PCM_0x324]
BO_ 777 PCM_0x309: 8 METER
 SG_ unknown2 : 16|8@1+ (1,0) [0|255] ""  PCM
 SG_ unknown3 : 24|8@1+ (1,0) [0|255] ""  PCM
 SG_ Speed : 39|16@0+ (0.01,0) [0|655.35] "km/h"  PCM
 SG_ unknown4 : 48|8@1+ (1,0) [0|255] ""  PCM
 SG_ CHECKSUM : 56|4@1+ (1,0) [0|15] ""  PCM
 SG_ COUNTER : 60|2@1+ (1,0) [0|3] ""  PCM
 SG_ SECONDARY_SPEEDLIKE_WORD_RAW_TBD : 7|16@0+ (1,0) [0|0] ""  PCM
 SG_ SPEED_STATUS_D7B6_TBD : 62|1@1+ (1,0) [0|0] ""  PCM
 SG_ SPEED_STATUS_D7B7_TBD : 63|1@1+ (1,0) [0|0] ""  PCM

CM_ BO_ 800 "TX ACTIVE; DLC8; direction relative to PCM.";
BO_ 800 BCM_0x320: 8 PCM
 SG_ rsvd0 : 0|6@1+ (1,0) [0|63] ""  UNKNOWN
 SG_ EngineStateCodeTBD : 6|2@1+ (1,0) [0|3] ""  UNKNOWN
 SG_ STATUS_BIT_1_TBD : 8|1@1+ (1,0) [0|1] ""  UNKNOWN
 SG_ STATUS_BIT_2_TBD : 9|1@1+ (1,0) [0|1] ""  UNKNOWN
 SG_ rsvd1 : 10|4@1+ (1,0) [0|15] ""  UNKNOWN
 SG_ STATUS_BIT_3_TBD : 14|1@1+ (1,0) [0|1] ""  UNKNOWN
 SG_ rsvd2 : 15|1@1+ (1,0) [0|1] ""  UNKNOWN
 SG_ StateCodeB2_TBD : 16|3@1+ (1,0) [0|7] ""  UNKNOWN
 SG_ SignedCapOutOfDomainHighBitsB2_T : 19|3@1+ (1,0) [0|7] ""  UNKNOWN
 SG_ STATUS_BIT_4_TBD : 22|1@1+ (1,0) [0|1] ""  UNKNOWN
 SG_ SignedCapOutOfDomainSignBitB2_TB : 23|1@1+ (1,0) [0|1] ""  UNKNOWN
 SG_ rsvd3 : 24|8@1+ (1,0) [0|255] ""  UNKNOWN
 SG_ rsvd4 : 32|7@1+ (1,0) [0|127] ""  UNKNOWN
 SG_ STATUS_BIT_5_TBD : 39|1@1+ (1,0) [0|1] ""  UNKNOWN
 SG_ StateCodeB5Low_TBD : 40|3@1+ (1,0) [0|7] ""  UNKNOWN
 SG_ StateCodeB5High_TBD : 43|3@1+ (1,0) [0|7] ""  UNKNOWN
 SG_ SignedCapOutOfDomainHighBitsB5_T : 46|2@1+ (1,0) [0|3] ""  UNKNOWN
 SG_ STATUS_BIT_6_TBD : 48|1@1+ (1,0) [0|1] ""  UNKNOWN
 SG_ rsvd5 : 49|2@1+ (1,0) [0|3] ""  UNKNOWN
 SG_ STATUS_BIT_7_TBD : 51|1@1+ (1,0) [0|1] ""  UNKNOWN
 SG_ rsvd6 : 52|4@1+ (1,0) [0|15] ""  UNKNOWN
 SG_ CHECKSUM : 56|4@1+ (1,0) [0|15] ""  UNKNOWN
 SG_ COUNTER : 60|2@1+ (1,0) [0|3] ""  UNKNOWN
 SG_ STATUS_BIT_8_TBD : 62|1@1+ (1,0) [0|1] ""  UNKNOWN
 SG_ STATUS_BIT_9_TBD : 63|1@1+ (1,0) [0|1] ""  UNKNOWN

CM_ BO_ 804 "TX ACTIVE; DLC8; direction relative to PCM.";
CM_ SG_ 804 IMMOBILIZER_REPORTING_CODE "0 complete+accepted; 1 incomplete; 2 complete+not-accepted. HDS IMBLIZ uses another encoding; no physical authorization claim.";
CM_ SG_ 804 IAT "Raw FF is invalid.";
CM_ SG_ 804 ECT "Raw FF is invalid.";
BO_ 804 PCM_0x324: 8 PCM
 SG_ ECT : 0|8@1+ (1,-40) [-40|215] "degC"  UNKNOWN
 SG_ IAT : 8|8@1+ (1,-40) [-40|215] "degC"  UNKNOWN
 SG_ tripFuelCosumed : 23|16@0+ (1,0) [0|65535] ""  UNKNOWN
 SG_ CRUISE_SET_SPEED_PRESENTATION_KP : 32|8@1+ (1,0) [0|255] "raw"  UNKNOWN
 SG_ ESTIMATED_ROAD_GRADE_RAW : 40|8@1- (0.125,0) [-16|15.875] ""  UNKNOWN
 SG_ SCS : 48|1@1+ (1,0) [0|1] ""  UNKNOWN
 SG_ TIMED_MONITOR_HOLD_RAW : 49|1@1+ (1,0) [0|1] ""  UNKNOWN
 SG_ DIAGNOSTIC_MONITOR_STATE_INVERTE : 50|1@1+ (1,0) [0|1] ""  UNKNOWN
 SG_ MONITOR_CACHE_INVERTED_RAW : 51|1@1+ (1,0) [0|1] ""  UNKNOWN
 SG_ IMMOBILIZER_REPORTING_CODE : 52|2@1+ (1,0) [0|3] ""  UNKNOWN
 SG_ rsvd0 : 54|1@1+ (1,0) [0|1] ""  UNKNOWN
 SG_ TIMED_CONTROLLER_STATE_RAW : 55|1@1+ (1,0) [0|1] ""  UNKNOWN
 SG_ CHECKSUM : 56|4@1+ (1,0) [0|15] ""  UNKNOWN
 SG_ COUNTER : 60|2@1+ (1,0) [0|3] ""  UNKNOWN
 SG_ ROUTINE_020E_ACTIVE_RAW : 62|1@1+ (1,0) [0|1] ""  UNKNOWN
 SG_ DIAGNOSTIC_MONITOR_STATE_IN_0000 : 63|1@1+ (1,0) [0|1] ""  UNKNOWN

CM_ BO_ 808 "TX ACTIVE; DLC8; direction relative to PCM.";
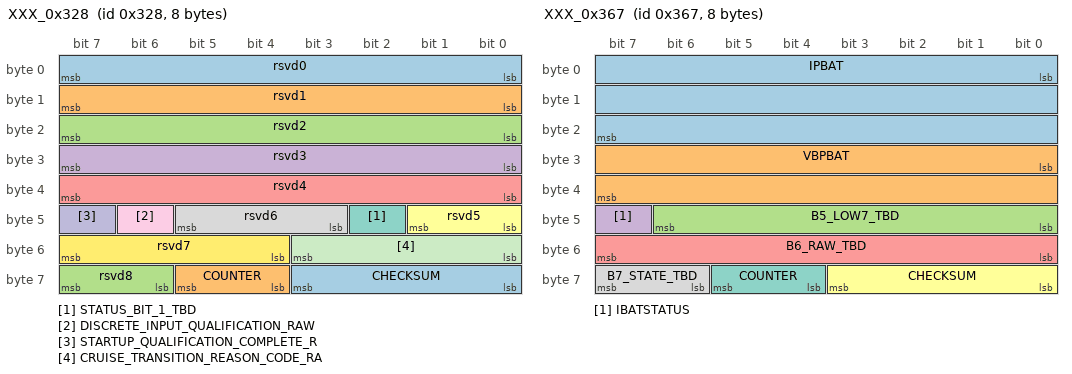
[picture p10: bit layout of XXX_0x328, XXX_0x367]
BO_ 808 XXX_0x328: 8 PCM
 SG_ rsvd0 : 0|8@1+ (1,0) [0|255] ""  UNKNOWN
 SG_ rsvd1 : 8|8@1+ (1,0) [0|255] ""  UNKNOWN
 SG_ rsvd2 : 16|8@1+ (1,0) [0|255] ""  UNKNOWN
 SG_ rsvd3 : 24|8@1+ (1,0) [0|255] ""  UNKNOWN
 SG_ rsvd4 : 32|8@1+ (1,0) [0|255] ""  UNKNOWN
 SG_ rsvd5 : 40|2@1+ (1,0) [0|3] ""  UNKNOWN
 SG_ STATUS_BIT_1_TBD : 42|1@1+ (1,0) [0|1] ""  UNKNOWN
 SG_ rsvd6 : 43|3@1+ (1,0) [0|7] ""  UNKNOWN
 SG_ DISCRETE_INPUT_QUALIFICATION_RAW : 46|1@1+ (1,0) [0|1] ""  UNKNOWN
 SG_ STARTUP_QUALIFICATION_COMPLETE_R : 47|1@1+ (1,0) [0|1] ""  UNKNOWN
 SG_ CRUISE_TRANSITION_REASON_CODE_RA : 48|4@1+ (1,0) [0|15] ""  UNKNOWN
 SG_ rsvd7 : 52|4@1+ (1,0) [0|15] ""  UNKNOWN
 SG_ CHECKSUM : 56|4@1+ (1,0) [0|15] ""  UNKNOWN
 SG_ COUNTER : 60|2@1+ (1,0) [0|3] ""  UNKNOWN
 SG_ rsvd8 : 62|2@1+ (1,0) [0|3] ""  UNKNOWN

CM_ BO_ 871 "RX ACTIVE; DLC8; direction relative to PCM. Battery data; signed/clamped derived current is nonlinear. Wire values preserve source status limits.";
BO_ 871 XXX_0x367: 8 METER
 SG_ IPBAT : 0|24@1+ (1,0) [0|16777215] "raw"  PCM
 SG_ VBPBAT : 24|16@1+ (0.001,0) [0|65.535] "V"  PCM
 SG_ B5_LOW7_TBD : 40|7@1+ (1,0) [0|127] ""  PCM
 SG_ IBATSTATUS : 47|1@1+ (1,0) [0|1] ""  PCM
 SG_ B6_RAW_TBD : 48|8@1+ (1,0) [0|255] ""  PCM
 SG_ CHECKSUM : 56|4@1+ (1,0) [0|15] ""  PCM
 SG_ COUNTER : 60|2@1+ (1,0) [0|3] ""  PCM
 SG_ B7_STATE_TBD : 62|2@1+ (1,0) [0|3] ""  PCM

CM_ BO_ 882 "RX ACTIVE; DLC2; direction relative to PCM.";
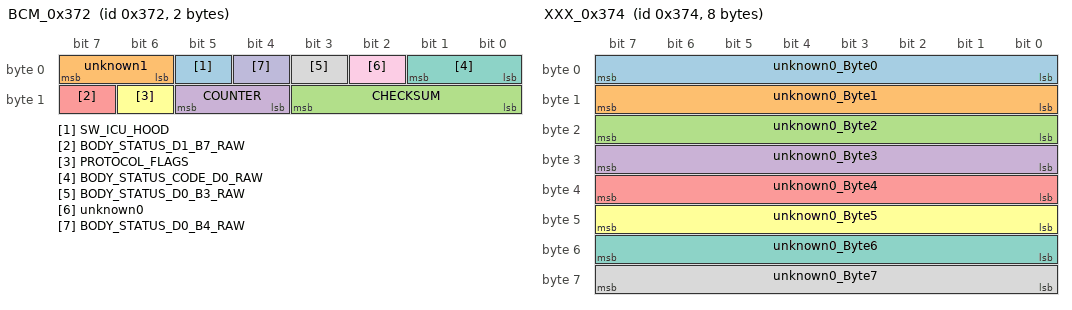
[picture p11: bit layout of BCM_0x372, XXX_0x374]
BO_ 882 BCM_0x372: 2 METER
 SG_ SW_ICU_HOOD : 5|1@1+ (1,0) [0|1] ""  PCM
 SG_ unknown1 : 6|2@1+ (1,0) [0|3] ""  PCM
 SG_ CHECKSUM : 8|4@1+ (1,0) [0|15] ""  PCM
 SG_ COUNTER : 12|2@1+ (1,0) [0|3] ""  PCM
 SG_ BODY_STATUS_D1_B7_RAW : 15|1@1+ (1,0) [0|0] ""  PCM
 SG_ PROTOCOL_FLAGS : 14|1@1+ (1,0) [0|0] ""  PCM
 SG_ BODY_STATUS_CODE_D0_RAW : 0|2@1+ (1,0) [0|0] ""  PCM
 SG_ BODY_STATUS_D0_B3_RAW : 3|1@1+ (1,0) [0|0] ""  PCM
 SG_ unknown0 : 2|1@1+ (1,0) [0|0] ""  PCM
 SG_ BODY_STATUS_D0_B4_RAW : 4|1@1+ (1,0) [0|0] ""  PCM

CM_ BO_ 884 "No saved selected registration; bus presence unproved; direction relative to PCM.";
BO_ 884 XXX_0x374: 8 UNKNOWN
 SG_ unknown0_Byte0 : 0|8@1+ (1,0) [0|255] ""  UNKNOWN
 SG_ unknown0_Byte1 : 8|8@1+ (1,0) [0|255] ""  UNKNOWN
 SG_ unknown0_Byte2 : 16|8@1+ (1,0) [0|255] ""  UNKNOWN
 SG_ unknown0_Byte3 : 24|8@1+ (1,0) [0|255] ""  UNKNOWN
 SG_ unknown0_Byte4 : 32|8@1+ (1,0) [0|255] ""  UNKNOWN
 SG_ unknown0_Byte5 : 40|8@1+ (1,0) [0|255] ""  UNKNOWN
 SG_ unknown0_Byte6 : 48|8@1+ (1,0) [0|255] ""  UNKNOWN
 SG_ unknown0_Byte7 : 56|8@1+ (1,0) [0|255] ""  UNKNOWN

CM_ BO_ 891 "No saved selected registration; bus presence unproved; direction relative to PCM.";
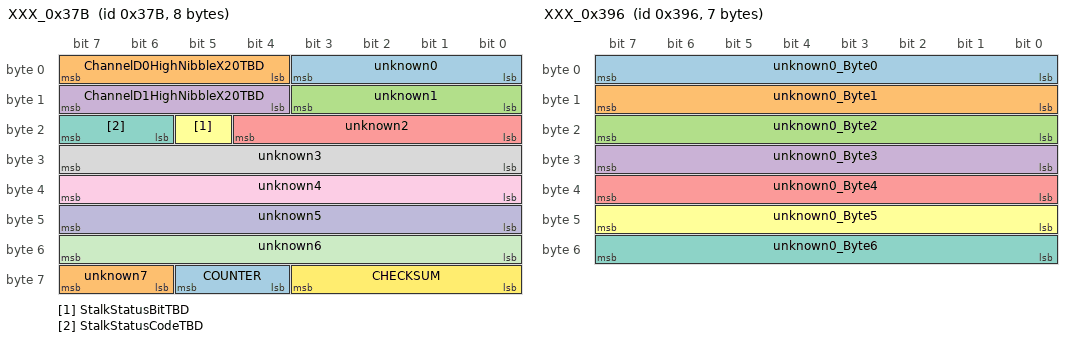
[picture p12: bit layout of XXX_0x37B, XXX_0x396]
BO_ 891 XXX_0x37B: 8 METER
 SG_ unknown0 : 0|4@1+ (1,0) [0|15] ""  PCM
 SG_ ChannelD0HighNibbleX20TBD : 4|4@1+ (1,0) [0|15] ""  PCM
 SG_ unknown1 : 8|4@1+ (1,0) [0|15] ""  PCM
 SG_ ChannelD1HighNibbleX20TBD : 12|4@1+ (1,0) [0|15] ""  PCM
 SG_ unknown2 : 16|5@1+ (1,0) [0|31] ""  PCM
 SG_ StalkStatusBitTBD : 21|1@1+ (1,0) [0|1] ""  PCM
 SG_ StalkStatusCodeTBD : 22|2@1+ (1,0) [0|3] ""  PCM
 SG_ unknown3 : 24|8@1+ (1,0) [0|255] ""  PCM
 SG_ unknown4 : 32|8@1+ (1,0) [0|255] ""  PCM
 SG_ unknown5 : 40|8@1+ (1,0) [0|255] ""  PCM
 SG_ unknown6 : 48|8@1+ (1,0) [0|255] ""  PCM
 SG_ CHECKSUM : 56|4@1+ (1,0) [0|15] ""  PCM
 SG_ COUNTER : 60|2@1+ (1,0) [0|3] ""  PCM
 SG_ unknown7 : 62|2@1+ (1,0) [0|3] ""  PCM

CM_ BO_ 918 "No saved selected registration; bus presence unproved; direction relative to PCM.";
BO_ 918 XXX_0x396: 7 UNKNOWN
 SG_ unknown0_Byte0 : 0|8@1+ (1,0) [0|255] ""  UNKNOWN
 SG_ unknown0_Byte1 : 8|8@1+ (1,0) [0|255] ""  UNKNOWN
 SG_ unknown0_Byte2 : 16|8@1+ (1,0) [0|255] ""  UNKNOWN
 SG_ unknown0_Byte3 : 24|8@1+ (1,0) [0|255] ""  UNKNOWN
 SG_ unknown0_Byte4 : 32|8@1+ (1,0) [0|255] ""  UNKNOWN
 SG_ unknown0_Byte5 : 40|8@1+ (1,0) [0|255] ""  UNKNOWN
 SG_ unknown0_Byte6 : 48|8@1+ (1,0) [0|255] ""  UNKNOWN

CM_ BO_ 929 "No saved selected registration; bus presence unproved; direction relative to PCM.";
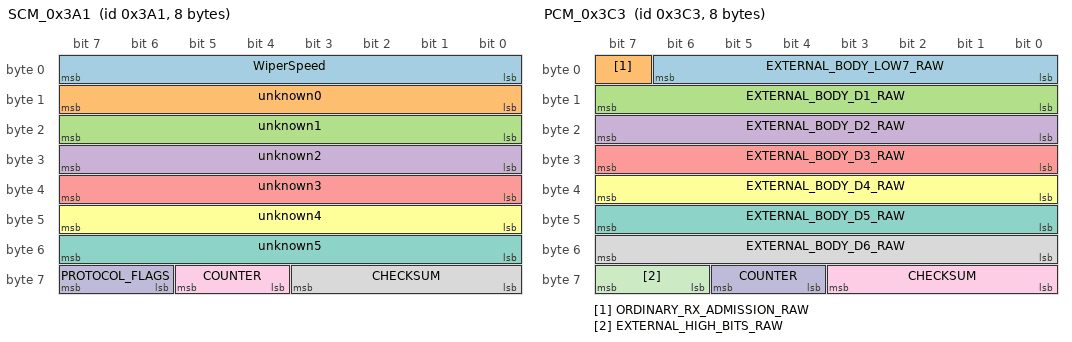
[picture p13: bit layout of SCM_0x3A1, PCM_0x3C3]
BO_ 929 SCM_0x3A1: 8 METER
 SG_ WiperSpeed : 0|8@1+ (1,0) [0|255] ""  UNKNOWN
 SG_ unknown0 : 8|8@1+ (1,0) [0|255] ""  UNKNOWN
 SG_ unknown1 : 16|8@1+ (1,0) [0|255] ""  UNKNOWN
 SG_ unknown2 : 24|8@1+ (1,0) [0|255] ""  UNKNOWN
 SG_ unknown3 : 32|8@1+ (1,0) [0|255] ""  UNKNOWN
 SG_ unknown4 : 40|8@1+ (1,0) [0|255] ""  UNKNOWN
 SG_ unknown5 : 48|8@1+ (1,0) [0|255] ""  UNKNOWN
 SG_ CHECKSUM : 56|4@1+ (1,0) [0|15] ""  UNKNOWN
 SG_ COUNTER : 60|2@1+ (1,0) [0|3] ""  UNKNOWN
 SG_ PROTOCOL_FLAGS : 62|2@1+ (1,0) [0|3] ""  UNKNOWN

CM_ BO_ 963 "TX ACTIVE; DLC8; direction relative to PCM. Retained RX3C5 body; PCM regenerates checksum/counter. Body may remain stale.";
BO_ 963 PCM_0x3C3: 8 PCM
 SG_ EXTERNAL_BODY_LOW7_RAW : 0|7@1+ (1,0) [0|0] ""  UNKNOWN
 SG_ ORDINARY_RX_ADMISSION_RAW : 7|1@1+ (1,0) [0|0] ""  UNKNOWN
 SG_ EXTERNAL_BODY_D1_RAW : 8|8@1+ (1,0) [0|0] ""  UNKNOWN
 SG_ EXTERNAL_BODY_D2_RAW : 16|8@1+ (1,0) [0|0] ""  UNKNOWN
 SG_ EXTERNAL_BODY_D3_RAW : 24|8@1+ (1,0) [0|0] ""  UNKNOWN
 SG_ EXTERNAL_BODY_D4_RAW : 32|8@1+ (1,0) [0|0] ""  UNKNOWN
 SG_ EXTERNAL_BODY_D5_RAW : 40|8@1+ (1,0) [0|0] ""  UNKNOWN
 SG_ EXTERNAL_BODY_D6_RAW : 48|8@1+ (1,0) [0|0] ""  UNKNOWN
 SG_ CHECKSUM : 56|4@1+ (1,0) [0|0] ""  UNKNOWN
 SG_ COUNTER : 60|2@1+ (1,0) [0|0] ""  UNKNOWN
 SG_ EXTERNAL_HIGH_BITS_RAW : 62|2@1+ (1,0) [0|0] ""  UNKNOWN

CM_ BO_ 967 "TX ACTIVE; DLC8; direction relative to PCM. Retained RX3C6 body; PCM regenerates checksum/counter. Body may remain stale.";
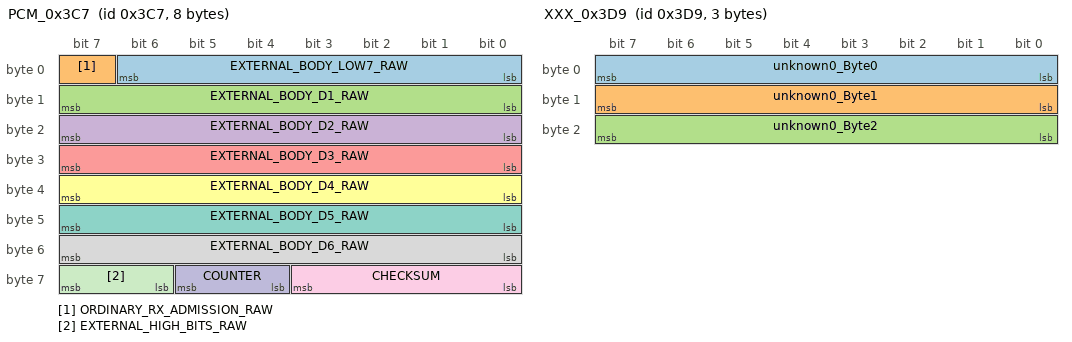
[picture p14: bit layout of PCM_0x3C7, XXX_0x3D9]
BO_ 967 PCM_0x3C7: 8 PCM
 SG_ EXTERNAL_BODY_LOW7_RAW : 0|7@1+ (1,0) [0|0] ""  UNKNOWN
 SG_ ORDINARY_RX_ADMISSION_RAW : 7|1@1+ (1,0) [0|0] ""  UNKNOWN
 SG_ EXTERNAL_BODY_D1_RAW : 8|8@1+ (1,0) [0|0] ""  UNKNOWN
 SG_ EXTERNAL_BODY_D2_RAW : 16|8@1+ (1,0) [0|0] ""  UNKNOWN
 SG_ EXTERNAL_BODY_D3_RAW : 24|8@1+ (1,0) [0|0] ""  UNKNOWN
 SG_ EXTERNAL_BODY_D4_RAW : 32|8@1+ (1,0) [0|0] ""  UNKNOWN
 SG_ EXTERNAL_BODY_D5_RAW : 40|8@1+ (1,0) [0|0] ""  UNKNOWN
 SG_ EXTERNAL_BODY_D6_RAW : 48|8@1+ (1,0) [0|0] ""  UNKNOWN
 SG_ CHECKSUM : 56|4@1+ (1,0) [0|0] ""  UNKNOWN
 SG_ COUNTER : 60|2@1+ (1,0) [0|0] ""  UNKNOWN
 SG_ EXTERNAL_HIGH_BITS_RAW : 62|2@1+ (1,0) [0|0] ""  UNKNOWN

CM_ BO_ 983 "TX ACTIVE; DLC8; direction relative to PCM.";
BO_ 983 PCM_0x3D7: 8 PCM
 SG_ MultiplexHeader : 0|8@1+ (1,0) [0|255] ""  UNKNOWN
 SG_ RetainedBankACodeWord0_Page0 m0 : 15|16@0+ (1,0) [0|65535] ""  UNKNOWN
 SG_ RetainedBankACodeWord0_Page1 m1 : 15|16@0+ (1,0) [0|65535] ""  UNKNOWN
 SG_ RetainedBankACodeWord1_Page0 m0 : 31|16@0+ (1,0) [0|65535] ""  UNKNOWN
 SG_ RetainedBankACodeWord1_Page1 m1 : 31|16@0+ (1,0) [0|65535] ""  UNKNOWN
 SG_ RetainedBankACodeWord2_Page0 m0 : 47|16@0+ (1,0) [0|65535] ""  UNKNOWN
 SG_ RetainedBankACodeWord2_Page1 m1 : 47|16@0+ (1,0) [0|65535] ""  UNKNOWN
 SG_ CHECKSUM : 56|4@1+ (1,0) [0|15] ""  UNKNOWN
 SG_ COUNTER : 60|2@1+ (1,0) [0|3] ""  UNKNOWN
 SG_ PageIndex M : 62|1@1+ (1,0) [0|1] ""  UNKNOWN
 SG_ ProtocolBit7 : 63|1@1+ (1,0) [0|1] ""  UNKNOWN

CM_ BO_ 985 "No saved selected registration; bus presence unproved; direction relative to PCM.";
BO_ 985 XXX_0x3D9: 3 VSA
 SG_ unknown0_Byte0 : 0|8@1+ (1,0) [0|255] ""  UNKNOWN
 SG_ unknown0_Byte1 : 8|8@1+ (1,0) [0|255] ""  UNKNOWN
 SG_ unknown0_Byte2 : 16|8@1+ (1,0) [0|255] ""  UNKNOWN

CM_ BO_ 1024 "TX ACTIVE; DLC5; direction relative to PCM.";
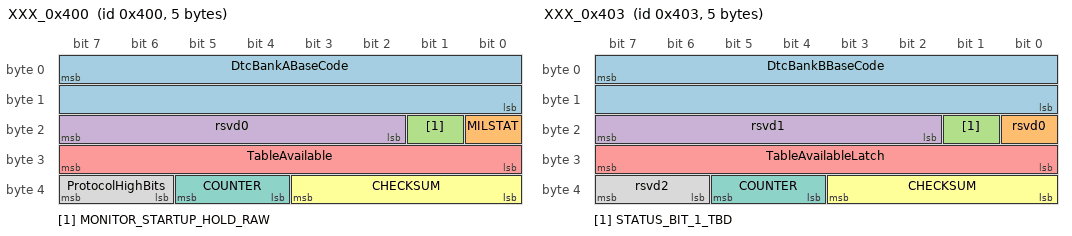
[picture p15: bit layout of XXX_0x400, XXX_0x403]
BO_ 1024 XXX_0x400: 5 PCM
 SG_ DtcBankABaseCode : 7|16@0+ (1,0) [0|65535] ""  UNKNOWN
 SG_ MILSTAT : 16|1@1+ (1,0) [0|1] ""  UNKNOWN
 SG_ MONITOR_STARTUP_HOLD_RAW : 17|1@1+ (1,0) [0|1] ""  UNKNOWN
 SG_ rsvd0 : 18|6@1+ (1,0) [0|63] ""  UNKNOWN
 SG_ TableAvailable : 24|8@1+ (1,0) [0|255] ""  UNKNOWN
 SG_ CHECKSUM : 32|4@1+ (1,0) [0|15] ""  UNKNOWN
 SG_ COUNTER : 36|2@1+ (1,0) [0|3] ""  UNKNOWN
 SG_ ProtocolHighBits : 38|2@1+ (1,0) [0|3] ""  UNKNOWN

CM_ BO_ 1027 "TX ACTIVE; DLC5; direction relative to PCM.";
BO_ 1027 XXX_0x403: 5 PCM
 SG_ DtcBankBBaseCode : 7|16@0+ (1,0) [0|65535] ""  UNKNOWN
 SG_ rsvd0 : 16|1@1+ (1,0) [0|1] ""  UNKNOWN
 SG_ STATUS_BIT_1_TBD : 17|1@1+ (1,0) [0|1] ""  UNKNOWN
 SG_ rsvd1 : 18|6@1+ (1,0) [0|63] ""  UNKNOWN
 SG_ TableAvailableLatch : 24|8@1+ (1,0) [0|255] ""  UNKNOWN
 SG_ CHECKSUM : 32|4@1+ (1,0) [0|15] ""  UNKNOWN
 SG_ COUNTER : 36|2@1+ (1,0) [0|3] ""  UNKNOWN
 SG_ rsvd2 : 38|2@1+ (1,0) [0|3] ""  UNKNOWN

CM_ BO_ 1029 "No saved selected registration; bus presence unproved; direction relative to PCM. Pilot reference paths; installed source and physical lamp identities remain qualified.";
BO_ 1029 SCM_0x405: 8 METER
 SG_ unknown3 : 24|8@1+ (1,0) [0|255] ""  UNKNOWN
 SG_ unknown4 : 32|5@1+ (1,0) [0|31] ""  UNKNOWN
 SG_ DoorOpenFL : 37|1@1+ (1,0) [0|1] ""  UNKNOWN
 SG_ DoorOpenFR : 38|1@1+ (1,0) [0|1] ""  UNKNOWN
 SG_ DoorOpenRL : 39|1@1+ (1,0) [0|1] ""  UNKNOWN
 SG_ DoorOpenRR : 40|1@1+ (1,0) [0|1] ""  UNKNOWN
 SG_ TrunkOpen : 41|1@1+ (1,0) [0|1] ""  UNKNOWN
 SG_ unknown6 : 48|8@1+ (1,0) [0|255] ""  UNKNOWN
 SG_ CHECKSUM : 56|4@1+ (1,0) [0|15] ""  UNKNOWN
 SG_ COUNTER : 60|2@1+ (1,0) [0|3] ""  UNKNOWN
 SG_ PROTOCOL_FLAGS : 62|2@1+ (1,0) [0|3] ""  UNKNOWN
 SG_ MIL_DERIVED_STATUS : 0|1@1+ (1,0) [0|0] ""  UNKNOWN
 SG_ unknown0 : 1|7@1+ (1,0) [0|0] ""  UNKNOWN
 SG_ SHARED_431DC_STATUS_D2B3_TBD : 19|1@1+ (1,0) [0|0] ""  UNKNOWN
 SG_ unknown2 : 20|4@1+ (1,0) [0|0] ""  UNKNOWN
 SG_ IMMOBILIZER_LAMP_STATE_TBD : 42|1@1+ (1,0) [0|0] ""  UNKNOWN
 SG_ unknown5 : 43|5@1+ (1,0) [0|0] ""  UNKNOWN
 SG_ REFERENCE_RX333_D0B2_NONZERO : 15|1@1+ (1,0) [0|0] ""  UNKNOWN
 SG_ REFERENCE_RX333_D0B3_NONZERO : 14|1@1+ (1,0) [0|0] ""  UNKNOWN
 SG_ unknown1 : 8|6@1+ (1,0) [0|0] ""  UNKNOWN
 SG_ REFERENCE_RX333_D0B4_NONZERO : 17|1@1+ (1,0) [0|0] ""  UNKNOWN
 SG_ REFERENCE_RX333_D0B5_NONZERO : 16|1@1+ (1,0) [0|0] ""  UNKNOWN
 SG_ unknown2_part1 : 18|1@1+ (1,0) [0|0] ""  UNKNOWN

CM_ BO_ 1030 "No saved selected registration; bus presence unproved; direction relative to PCM.";
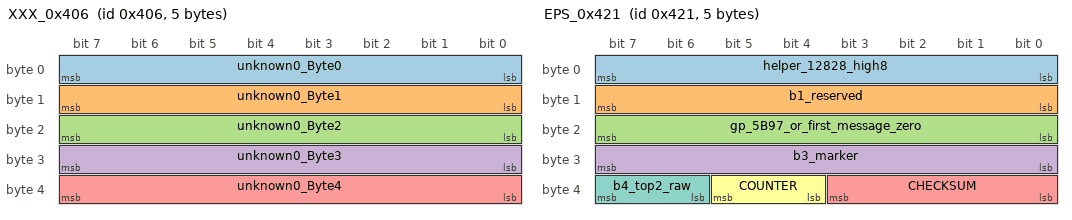
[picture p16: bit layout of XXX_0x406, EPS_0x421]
BO_ 1030 XXX_0x406: 5 UNKNOWN
 SG_ unknown0_Byte0 : 0|8@1+ (1,0) [0|255] ""  UNKNOWN
 SG_ unknown0_Byte1 : 8|8@1+ (1,0) [0|255] ""  UNKNOWN
 SG_ unknown0_Byte2 : 16|8@1+ (1,0) [0|255] ""  UNKNOWN
 SG_ unknown0_Byte3 : 24|8@1+ (1,0) [0|255] ""  UNKNOWN
 SG_ unknown0_Byte4 : 32|8@1+ (1,0) [0|255] ""  UNKNOWN

CM_ BO_ 1036 "TX ACTIVE; DLC8; direction relative to PCM. Multiplexed diagnostic caches; source sampling, gating and physical observations are separate.";
BO_ 1036 XXX_0x40C: 8 PCM
 SG_ MULTIPLEX_PAGE M : 0|4@1+ (1,0) [0|15] ""  UNKNOWN
 SG_ MULTIPLEX_GROUP : 4|2@1+ (1,0) [0|3] ""  UNKNOWN
 SG_ DIAGNOSTIC_EVENT_STATE : 6|2@1+ (1,0) [0|3] ""  UNKNOWN
 SG_ P00_ZERO_BYTE_B1_RAW m0 : 8|8@1+ (1,0) [0|255] ""  UNKNOWN
 SG_ P01_VIN_CHARACTER1_B1_RAW m1 : 8|8@1+ (1,0) [0|255] ""  UNKNOWN
 SG_ P02_VIN_CHARACTER7_B1_RAW m2 : 8|8@1+ (1,0) [0|255] ""  UNKNOWN
 SG_ P03_VIN_CHARACTER13_B1_RAW m3 : 8|8@1+ (1,0) [0|255] ""  UNKNOWN
 SG_ P04_VARIANTCONFIGBYTE1_B1_RAW m4 : 8|8@1+ (1,0) [0|255] ""  UNKNOWN
 SG_ P05_NE m5 : 15|16@0+ (0.25,0) [0|16383.75] "rpm"  UNKNOWN
 SG_ P06_IAT_SENSOR_VOLTAGE_B1_RAW m6 : 8|8@1+ (0.0196078431372549,0) [0|5] "V"  UNKNOWN
 SG_ P07_VEHICLESPEED_B1_RAW m7 : 8|8@1+ (1,0) [0|255] "km/h"  UNKNOWN
 SG_ P08_APP m8 : 15|16@0+ (0.005,0) [0|327.675] "%"  UNKNOWN
 SG_ P09_THO m9 : 15|16@0+ (0.005,0) [0|327.675] "deg"  UNKNOWN
 SG_ P0A_XILAF_B1 m10 : 15|16@0+ (1,0) [0|65535] ""  UNKNOWN
 SG_ P0B_STATUS_BIT_1_TBD m11 : 8|8@1+ (1,0) [0|255] ""  UNKNOWN
 SG_ P0C_KLAF_B2 m12 : 8|8@1+ (0.0078125,0) [0|1.9921875] "ratio"  UNKNOWN
 SG_ P0D_LIFT m13 : 8|8@1+ (1,0) [0|255] ""  UNKNOWN
 SG_ P0E_MASSAIRFLOW m14 : 15|16@0+ (0.01,0) [0|655.35] "g/s"  UNKNOWN
 SG_ P0F_FUELTANKLEVELINPUT_B1_RAW m15 : 8|8@1+ (0.39215686274509803,0) [0|100] "%"  UNKNOWN
 SG_ P00_DIAGNOSTIC_EVENT_CACHE_WORD m0 : 23|16@0+ (1,0) [0|65535] ""  UNKNOWN
 SG_ P01_VIN_CHARACTER2_B2_RAW m1 : 16|8@1+ (1,0) [0|255] ""  UNKNOWN
 SG_ P02_VIN_CHARACTER8_B2_RAW m2 : 16|8@1+ (1,0) [0|255] ""  UNKNOWN
 SG_ P03_VIN_CHARACTER14_B2_RAW m3 : 16|8@1+ (1,0) [0|255] ""  UNKNOWN
 SG_ P04_VARIANTCONFIGBYTE2_B2_RAW m4 : 16|8@1+ (1,0) [0|255] ""  UNKNOWN
 SG_ P06_INTAKEAIRTEMPERATURE_B2_RAW m6 : 16|8@1+ (1,-40) [-40|215] "degC"  UNKNOWN
 SG_ P07_CALCULATEDENGINELOAD_B2_RAW m7 : 16|8@1+ (0.39215686274509803,0) [0|100] "%"  UNKNOWN
 SG_ P0B_SVO2_B1 m11 : 16|8@1+ (0.0196078431372549,0) [0|5] "V"  UNKNOWN
 SG_ P0C_KLAFAVE_B2 m12 : 16|8@1+ (0.0078125,0) [0|1.9921875] "ratio"  UNKNOWN
 SG_ P0D_ZERO_BYTE_B2_RAW m13 : 16|8@1+ (1,0) [0|255] ""  UNKNOWN
 SG_ P0F_ZERO_BYTE_B2_RAW m15 : 16|8@1+ (1,0) [0|255] ""  UNKNOWN
 SG_ P01_VIN_CHARACTER3_B3_RAW m1 : 24|8@1+ (1,0) [0|255] ""  UNKNOWN
 SG_ P02_VIN_CHARACTER9_B3_RAW m2 : 24|8@1+ (1,0) [0|255] ""  UNKNOWN
 SG_ P03_VIN_CHARACTER15_B3_RAW m3 : 24|8@1+ (1,0) [0|255] ""  UNKNOWN
 SG_ P04_VARIANTCONFIGBYTE3_B3_RAW m4 : 24|8@1+ (1,0) [0|255] ""  UNKNOWN
 SG_ P05_THROTTLEPOSITION_B3_RAW m5 : 24|8@1+ (0.39215686274509803,0) [0|100] "%"  UNKNOWN
 SG_ P06_MAP_SENSOR_VOLTAGE_B3_RAW m6 : 24|8@1+ (0.0196078431372549,0) [0|5] "V"  UNKNOWN
 SG_ P07_IG m7 : 24|8@1+ (0.5,-64) [-64|63.5] "deg"  UNKNOWN
 SG_ P08_TH_1 m8 : 24|8@1+ (0.0196078431372549,0) [0|5] "V"  UNKNOWN
 SG_ P09_LEARNEDBASELINEA_RAW_UNRESOL m9 : 24|8@1+ (1,0) [0|255] ""  UNKNOWN
 SG_ P0A_LAMBDA_B1 m10 : 31|16@0+ (3.0517578125e-05,0) [0|1.999969482421875] "ratio"  UNKNOWN
 SG_ P0B_XILAF_B2 m11 : 31|16@0+ (1,0) [0|65535] ""  UNKNOWN
 SG_ P0C_STATUS_BIT_1_TBD m12 : 24|8@1+ (1,0) [0|255] ""  UNKNOWN
 SG_ P0D_ZERO_BYTE_B3_RAW m13 : 24|8@1+ (1,0) [0|255] ""  UNKNOWN
 SG_ P0E_ZERO_BYTE_B3_RAW m14 : 24|8@1+ (1,0) [0|255] ""  UNKNOWN
 SG_ P0F_ZERO_BYTE_B3_RAW m15 : 24|8@1+ (1,0) [0|255] ""  UNKNOWN
 SG_ P00_FORMAT_0X10_B4_RAW m0 : 32|8@1+ (1,0) [0|255] ""  UNKNOWN
 SG_ P01_VIN_CHARACTER4_B4_RAW m1 : 32|8@1+ (1,0) [0|255] ""  UNKNOWN
 SG_ P02_VIN_CHARACTER10_B4_RAW m2 : 32|8@1+ (1,0) [0|255] ""  UNKNOWN
 SG_ P03_VIN_CHARACTER16_B4_RAW m3 : 32|8@1+ (1,0) [0|255] ""  UNKNOWN
 SG_ P04_VARIANTCONFIGBYTE4_B4_RAW m4 : 32|8@1+ (1,0) [0|255] ""  UNKNOWN
 SG_ P05_RELATIVETHROTTLEPOSITION_B4_ m5 : 32|8@1+ (0.39215686274509803,0) [0|100] "%"  UNKNOWN
 SG_ P06_MANIFOLDABSOLUTEPRESSURE_B4_ m6 : 32|8@1+ (1,0) [0|255] "kPa"  UNKNOWN
 SG_ P07_CONTROL_MODULE_VOLTAGE_DECIV m7 : 32|8@1+ (0.1,0) [0|25.5] "V"  UNKNOWN
 SG_ P08_TH_2 m8 : 32|8@1+ (0.0196078431372549,0) [0|5] "V"  UNKNOWN
 SG_ P09_LEARNEDBASELINEB_RAW_UNRESOL m9 : 32|8@1+ (1,0) [0|255] ""  UNKNOWN
 SG_ P0C_SVO2_B2 m12 : 32|8@1+ (0.0196078431372549,0) [0|5] "V"  UNKNOWN
 SG_ P0D_AFM m13 : 32|8@1+ (0.0196078431372549,0) [0|5] "V"  UNKNOWN
 SG_ P0E_RUNTIMESINCEENGINESTART m14 : 39|16@0+ (1,0) [0|65535] "s"  UNKNOWN
 SG_ P0F_ZERO_BYTE_B4_RAW m15 : 32|8@1+ (1,0) [0|255] ""  UNKNOWN
 SG_ P00_ZERO_BYTE_B5_RAW m0 : 40|8@1+ (1,0) [0|255] ""  UNKNOWN
 SG_ P01_VIN_CHARACTER5_B5_RAW m1 : 40|8@1+ (1,0) [0|255] ""  UNKNOWN
 SG_ P02_VIN_CHARACTER11_B5_RAW m2 : 40|8@1+ (1,0) [0|255] ""  UNKNOWN
 SG_ P03_VIN_CHARACTER17_B5_RAW m3 : 40|8@1+ (1,0) [0|255] ""  UNKNOWN
 SG_ P04_VARIANTCONFIGBYTE5_B5_RAW m4 : 40|8@1+ (1,0) [0|255] ""  UNKNOWN
 SG_ P05_ECT_SENSOR_VOLTAGE_B5_RAW m5 : 40|8@1+ (0.0196078431372549,0) [0|5] "V"  UNKNOWN
 SG_ P06_BARO_SENSOR_VOLTAGE_B5_RAW m6 : 40|8@1+ (0.0196078431372549,0) [0|5] "V"  UNKNOWN
 SG_ P07_APP_SENSOR_A_VOLTAGE_B5_RAW m7 : 40|8@1+ (0.0196078431372549,0) [0|5] "V"  UNKNOWN
 SG_ P08_RELTHW m8 : 47|16@0+ (0.005,0) [0|327.675] "deg"  UNKNOWN
 SG_ P09_THICMD m9 : 47|16@0+ (0.005,0) [0|327.675] "deg"  UNKNOWN
 SG_ P0A_SHORTTERMFUELTRIMBANK1_B5_RA m10 : 40|8@1+ (0.78125,-100) [-100|99.21875] "%"  UNKNOWN
 SG_ P0B_LAMBDA_B2 m11 : 47|16@0+ (3.0517578125e-05,0) [0|1.999969482421875] "ratio"  UNKNOWN
 SG_ P0C_TOUT m12 : 47|16@0+ (0.004,0) [0|262.14] "ms"  UNKNOWN
 SG_ P0D_ZERO_BYTE_B5_RAW m13 : 40|8@1+ (1,0) [0|255] ""  UNKNOWN
 SG_ P0F_ZERO_BYTE_B5_RAW m15 : 40|8@1+ (1,0) [0|255] ""  UNKNOWN
 SG_ P00_ZERO_BYTE_B6_RAW m0 : 48|8@1+ (1,0) [0|255] ""  UNKNOWN
 SG_ P01_VIN_CHARACTER6_B6_RAW m1 : 48|8@1+ (1,0) [0|255] ""  UNKNOWN
 SG_ P02_VIN_CHARACTER12_B6_RAW m2 : 48|8@1+ (1,0) [0|255] ""  UNKNOWN
 SG_ P03_IDENTIFICATIONEXTRABYTE_RAW_ m3 : 48|8@1+ (1,0) [0|255] ""  UNKNOWN
 SG_ P04_ZERO_BYTE_B6_RAW m4 : 48|8@1+ (1,0) [0|255] ""  UNKNOWN
 SG_ P05_ENGINECOOLANTTEMPERATURE_B6_ m5 : 48|8@1+ (1,-40) [-40|215] "degC"  UNKNOWN
 SG_ P06_BAROMETRICPRESSURE_B6_RAW m6 : 48|8@1+ (1,0) [0|255] "kPa"  UNKNOWN
 SG_ P07_APP_SENSOR_B_VOLTAGE_B6_RAW m7 : 48|8@1+ (0.0196078431372549,0) [0|5] "V"  UNKNOWN
 SG_ P0A_LONGTERMFUELTRIMBANK1_B6_RAW m10 : 48|8@1+ (0.78125,-100) [-100|99.21875] "%"  UNKNOWN
 SG_ P0D_ZERO_BYTE_B6_RAW m13 : 48|8@1+ (1,0) [0|255] ""  UNKNOWN
 SG_ P0E_COMMANDEDEVAPORATIVEPURGE_B6 m14 : 48|8@1+ (0.39215686274509803,0) [0|100] "%"  UNKNOWN
 SG_ P0F_ZERO_BYTE_B6_RAW m15 : 48|8@1+ (1,0) [0|255] ""  UNKNOWN
 SG_ CHECKSUM : 56|4@1+ (1,0) [0|15] ""  UNKNOWN
 SG_ COUNTER : 60|2@1+ (1,0) [0|3] ""  UNKNOWN
 SG_ DIAGNOSTIC_STATUS_FLAG6 : 62|1@1+ (1,0) [0|1] ""  UNKNOWN
 SG_ DIAGNOSTIC_STATUS_FLAG7 : 63|1@1+ (1,0) [0|1] ""  UNKNOWN

CM_ BO_ 1039 "TX ACTIVE; DLC8; direction relative to PCM.";
BO_ 1039 XXX_0x40F: 8 PCM
 SG_ MULTIPLEX_PAGE M : 0|4@1+ (1,0) [0|15] ""  UNKNOWN
 SG_ MULTIPLEX_GROUP : 4|2@1+ (1,0) [0|3] ""  UNKNOWN
 SG_ DIAGNOSTIC_EVENT_STATE : 6|2@1+ (1,0) [0|3] ""  UNKNOWN
 SG_ P00_PAGE0_FORMAT_RAW m0 : 8|8@1+ (1,0) [0|255] ""  UNKNOWN
 SG_ P01_CONFIG_BYTE1_RAW m1 : 8|8@1+ (1,0) [0|255] ""  UNKNOWN
 SG_ P02_NEW m2 : 8|8@1+ (50,0) [0|12750] "rpm"  UNKNOWN
 SG_ P03_TW m3 : 8|8@1+ (1,-40) [-40|215] "degC"  UNKNOWN
 SG_ P04_PAAD m4 : 8|8@1+ (0.0196,0) [0|4.998] "V"  UNKNOWN
 SG_ P05_NMW m5 : 15|16@0+ (1,0) [0|65535] "rpm"  UNKNOWN
 SG_ P06_IACTA m6 : 8|8@1+ (0.005,0) [0|1.2750000000000001] "A"  UNKNOWN
 SG_ P07_PLA m7 : 8|1@1+ (1,0) [0|1] ""  UNKNOWN
 SG_ UnspecifiedPage_rsvd0 m8 : 8|8@1+ (1,0) [0|255] ""  UNKNOWN
 SG_ P07_SHG m7 : 9|1@1+ (1,0) [0|1] ""  UNKNOWN
 SG_ P07_SHF m7 : 10|1@1+ (1,0) [0|1] ""  UNKNOWN
 SG_ P07_SHE m7 : 11|1@1+ (1,0) [0|1] ""  UNKNOWN
 SG_ P07_SHD m7 : 12|1@1+ (1,0) [0|1] ""  UNKNOWN
 SG_ P07_SHC m7 : 13|1@1+ (1,0) [0|1] ""  UNKNOWN
 SG_ P07_SHB m7 : 14|1@1+ (1,0) [0|1] ""  UNKNOWN
 SG_ P07_SHA m7 : 15|1@1+ (1,0) [0|1] ""  UNKNOWN
 SG_ P00_PAGE0_EVENT_RAW m0 : 23|16@0+ (1,0) [0|65535] ""  UNKNOWN
 SG_ P01_CONFIG_BYTE2_RAW m1 : 16|8@1+ (1,0) [0|255] ""  UNKNOWN
 SG_ P02_VNC m2 : 16|8@1+ (1,0) [0|255] "km/h"  UNKNOWN
 SG_ P03_VB m3 : 16|8@1+ (0.1,0) [0|25.5] "V"  UNKNOWN
 SG_ P04_PA m4 : 16|8@1+ (1,0) [0|255] "kPa"  UNKNOWN
 SG_ P06_ICMDB m6 : 16|8@1+ (0.005,0) [0|1.2750000000000001] "A"  UNKNOWN
 SG_ P07_TATFAD m7 : 16|8@1+ (0.0196,0) [0|4.998] "V"  UNKNOWN
 SG_ UnspecifiedPage_rsvd1 m8 : 16|8@1+ (1,0) [0|255] ""  UNKNOWN
 SG_ P01_CONFIG_BYTE3_RAW m1 : 24|8@1+ (1,0) [0|255] ""  UNKNOWN
 SG_ P02_VNM m2 : 24|8@1+ (1,0) [0|255] "km/h"  UNKNOWN
 SG_ P03_SO m3 : 24|8@1+ (1,0) [0|255] ""  UNKNOWN
 SG_ P04_NEW m4 : 31|16@0+ (1,0) [0|65535] "rpm"  UNKNOWN
 SG_ P05_APSAT m5 : 24|8@1+ (0.5,0) [0|127.5] "%"  UNKNOWN
 SG_ P06_IACTB m6 : 24|8@1+ (0.005,0) [0|1.2750000000000001] "A"  UNKNOWN
 SG_ P07_TATF m7 : 24|8@1+ (1,-40) [-40|215] "degC"  UNKNOWN
 SG_ UnspecifiedPage_rsvd2 m8 : 24|8@1+ (1,0) [0|255] ""  UNKNOWN
 SG_ P00_PAGE0_LENGTH_RAW m0 : 32|8@1+ (1,0) [0|255] ""  UNKNOWN
 SG_ P01_CONFIG_BYTE4_RAW m1 : 32|8@1+ (1,0) [0|255] ""  UNKNOWN
 SG_ P02_THAD1 m2 : 32|8@1+ (0.0196,0) [0|4.998] "V"  UNKNOWN
 SG_ P03_STATUS_RAW m3 : 32|8@1+ (1,0) [0|255] ""  UNKNOWN
 SG_ P05_APS1AD m5 : 32|8@1+ (0.0196,0) [0|4.998] "V"  UNKNOWN
 SG_ P06_ICMDC m6 : 32|8@1+ (0.005,0) [0|1.2750000000000001] "A"  UNKNOWN
 SG_ P07_IACTD m7 : 32|8@1+ (0.005,0) [0|1.2750000000000001] "A"  UNKNOWN
 SG_ UnspecifiedPage_rsvd3 m8 : 32|8@1+ (1,0) [0|255] ""  UNKNOWN
 SG_ P00_PAGE0_RESERVED_RAW m0 : 47|16@0+ (1,0) [0|65535] ""  UNKNOWN
 SG_ P01_CONFIG_BYTE5_RAW m1 : 40|8@1+ (1,0) [0|255] ""  UNKNOWN
 SG_ P02_RELTH m2 : 40|8@1+ (0.3921,0) [0|99.9855] "%"  UNKNOWN
 SG_ P03_PBAD m3 : 40|8@1+ (0.0196,0) [0|4.998] "V"  UNKNOWN
 SG_ P04_NCW m4 : 47|16@0+ (1,0) [0|65535] "rpm"  UNKNOWN
 SG_ P05_APS2AD m5 : 40|8@1+ (0.0196,0) [0|4.998] "V"  UNKNOWN
 SG_ P06_IACTC m6 : 40|8@1+ (0.005,0) [0|1.2750000000000001] "A"  UNKNOWN
 SG_ P07_ICMDD m7 : 40|8@1+ (0.005,0) [0|1.2750000000000001] "A"  UNKNOWN
 SG_ UnspecifiedPage_rsvd4 m8 : 40|8@1+ (1,0) [0|255] ""  UNKNOWN
 SG_ P01_CONFIG_BYTE6_RAW m1 : 48|8@1+ (1,0) [0|255] ""  UNKNOWN
 SG_ P02_TWAD m2 : 48|8@1+ (0.0196,0) [0|4.998] "V"  UNKNOWN
 SG_ P03_PB m3 : 48|8@1+ (1,0) [0|255] "kPa"  UNKNOWN
 SG_ P05_ICMDA m5 : 48|8@1+ (0.005,0) [0|1.2750000000000001] "A"  UNKNOWN
 SG_ P06_VSP m6 : 48|8@1+ (1,0) [0|255] "km/h"  UNKNOWN
 SG_ P07_OPPLSW m7 : 48|1@1+ (1,0) [0|1] ""  UNKNOWN
 SG_ UnspecifiedPage_rsvd5 m8 : 48|8@1+ (1,0) [0|255] ""  UNKNOWN
 SG_ P07_OPSWB m7 : 49|1@1+ (1,0) [0|1] ""  UNKNOWN
 SG_ P07_OPSWA m7 : 50|1@1+ (1,0) [0|1] ""  UNKNOWN
 SG_ P07_OP6SW m7 : 51|1@1+ (1,0) [0|1] ""  UNKNOWN
 SG_ P07_OP5SW m7 : 52|1@1+ (1,0) [0|1] ""  UNKNOWN
 SG_ P07_OP4SW m7 : 53|1@1+ (1,0) [0|1] ""  UNKNOWN
 SG_ P07_OP3SW m7 : 54|1@1+ (1,0) [0|1] ""  UNKNOWN
 SG_ P07_OP2SW m7 : 55|1@1+ (1,0) [0|1] ""  UNKNOWN
 SG_ CHECKSUM : 56|4@1+ (1,0) [0|15] ""  UNKNOWN
 SG_ COUNTER : 60|2@1+ (1,0) [0|3] ""  UNKNOWN
 SG_ PROTOCOL_FLAGS : 62|2@1+ (1,0) [0|3] ""  UNKNOWN

CM_ BO_ 1057 "No saved selected registration; bus presence unproved; direction relative to PCM.";
BO_ 1057 EPS_0x421: 5 EPS
 SG_ helper_12828_high8 : 0|8@1+ (1,0) [0|255] ""  UNKNOWN
 SG_ b1_reserved : 8|8@1+ (1,0) [0|255] ""  UNKNOWN
 SG_ gp_5B97_or_first_message_zero : 16|8@1+ (1,0) [0|255] ""  UNKNOWN
 SG_ b3_marker : 24|8@1+ (1,0) [0|255] ""  UNKNOWN
 SG_ CHECKSUM : 32|4@1+ (1,0) [0|15] ""  UNKNOWN
 SG_ COUNTER : 36|2@1+ (1,0) [0|3] ""  UNKNOWN
 SG_ b4_top2_raw : 38|2@1+ (1,0) [0|3] ""  UNKNOWN

CM_ BO_ 1064 "RX ACTIVE; DLC7; direction relative to PCM.";
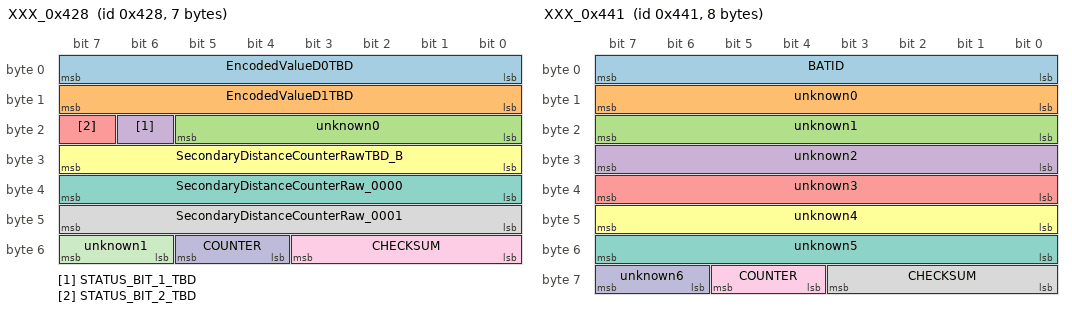
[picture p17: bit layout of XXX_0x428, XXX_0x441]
BO_ 1064 XXX_0x428: 7 METER
 SG_ EncodedValueD0TBD : 0|8@1+ (1,0) [0|255] ""  PCM
 SG_ EncodedValueD1TBD : 8|8@1+ (1,0) [0|255] ""  PCM
 SG_ unknown0 : 16|6@1+ (1,0) [0|63] ""  PCM
 SG_ STATUS_BIT_1_TBD : 22|1@1+ (1,0) [0|1] ""  PCM
 SG_ STATUS_BIT_2_TBD : 23|1@1+ (1,0) [0|1] ""  PCM
 SG_ SecondaryDistanceCounterRawTBD_B : 24|8@1+ (1,0) [0|255] ""  PCM
 SG_ SecondaryDistanceCounterRaw_0000 : 32|8@1+ (1,0) [0|255] ""  PCM
 SG_ SecondaryDistanceCounterRaw_0001 : 40|8@1+ (1,0) [0|255] ""  PCM
 SG_ CHECKSUM : 48|4@1+ (1,0) [0|15] ""  PCM
 SG_ COUNTER : 52|2@1+ (1,0) [0|3] ""  PCM
 SG_ unknown1 : 54|2@1+ (1,0) [0|3] ""  PCM

CM_ BO_ 1088 "RX ACTIVE; DLC8; direction relative to PCM. Multiplexed battery/cache records; nonlinear or unproved physical conversions remain raw.";
BO_ 1088 XXX_0x440: 8 METER
 SG_ Mux M : 0|8@1+ (1,0) [0|255] ""  PCM
 SG_ P31_unknown0 m49 : 8|8@1+ (1,0) [0|255] ""  PCM
 SG_ P32_RCLPBAT m50 : 8|16@1+ (1,0) [0|65535] "raw"  PCM
 SG_ P33_unknown0 m51 : 8|8@1+ (1,0) [0|255] ""  PCM
 SG_ P39_unknown0 m57 : 8|8@1+ (1,0) [0|255] ""  PCM
 SG_ P3A_page3A_temp_word_RAW m58 : 8|8@1+ (1,-40) [-40|215] "degC"  PCM
 SG_ UnspecifiedPage_unknown0 m0 : 8|8@1+ (1,0) [0|255] ""  PCM
 SG_ P31_unknown1 m49 : 16|8@1+ (1,0) [0|255] ""  PCM
 SG_ P33_unknown1 m51 : 16|8@1+ (1,0) [0|255] ""  PCM
 SG_ P39_unknown1 m57 : 16|8@1+ (1,0) [0|255] ""  PCM
 SG_ P3A_unknown0 m58 : 16|8@1+ (1,0) [0|255] ""  PCM
 SG_ UnspecifiedPage_unknown1 m0 : 16|8@1+ (1,0) [0|255] ""  PCM
 SG_ P31_TPBAT m49 : 24|8@1+ (1,-40) [-40|215] "degC"  PCM
 SG_ P32_raw34 m50 : 24|16@1+ (3.5172,0) [0|230499.702] "A*s"  PCM
 SG_ P33_unknown2 m51 : 24|8@1+ (1,0) [0|255] ""  PCM
 SG_ P39_VBATCO m57 : 24|8@1+ (4,4600) [4600|5620] "code"  PCM
 SG_ P3A_page3A_word34 m58 : 24|16@1+ (1,0) [0|65535] ""  PCM
 SG_ UnspecifiedPage_unknown2 m0 : 24|8@1+ (1,0) [0|255] ""  PCM
 SG_ P31_SOCPBAT m49 : 32|8@1+ (1,0) [0|255] "raw"  PCM
 SG_ P33_unknown3 m51 : 32|8@1+ (1,0) [0|255] ""  PCM
 SG_ P39_SOHQPBAT m57 : 32|8@1+ (1,0) [0|255] "raw"  PCM
 SG_ UnspecifiedPage_unknown3 m0 : 32|8@1+ (1,0) [0|255] ""  PCM
 SG_ P31_d5_low3 m49 : 40|3@1+ (1,0) [0|7] ""  PCM
 SG_ P32_raw56 m50 : 40|16@1+ (3.5172,0) [0|230499.702] "A*s"  PCM
 SG_ P33_unknown4 m51 : 40|8@1+ (1,0) [0|255] ""  PCM
 SG_ P39_SOFVPBAT m57 : 40|8@1+ (25,0) [0|6375] "code"  PCM
 SG_ P3A_unknown1 m58 : 40|8@1+ (1,0) [0|255] ""  PCM
 SG_ UnspecifiedPage_unknown4 m0 : 40|8@1+ (1,0) [0|255] ""  PCM
 SG_ P31_d5_mid2 m49 : 43|2@1+ (1,0) [0|3] ""  PCM
 SG_ P31_d5_bit5 m49 : 45|1@1+ (1,0) [0|1] ""  PCM
 SG_ P31_d5_bit6 m49 : 46|1@1+ (1,0) [0|1] ""  PCM
 SG_ P31_unknown2 m49 : 47|1@1+ (1,0) [0|1] ""  PCM
 SG_ P31_d6_low3 m49 : 48|3@1+ (1,0) [0|7] ""  PCM
 SG_ P33_unknown5 m51 : 48|8@1+ (1,0) [0|255] ""  PCM
 SG_ P39_BATSRST m57 : 48|1@1+ (1,0) [0|1] ""  PCM
 SG_ P3A_unknown2 m58 : 48|8@1+ (1,0) [0|255] ""  PCM
 SG_ UnspecifiedPage_unknown5 m0 : 48|8@1+ (1,0) [0|255] ""  PCM
 SG_ P39_BDCHGBAT m57 : 49|1@1+ (1,0) [0|1] ""  PCM
 SG_ P39_d6_bit2 m57 : 50|1@1+ (1,0) [0|1] ""  PCM
 SG_ P31_unknown3 m49 : 51|3@1+ (1,0) [0|7] ""  PCM
 SG_ P39_d6_bit3 m57 : 51|1@1+ (1,0) [0|1] ""  PCM
 SG_ P39_unknown2 m57 : 52|3@1+ (1,0) [0|7] ""  PCM
 SG_ P31_d6_bit6 m49 : 54|1@1+ (1,0) [0|1] ""  PCM
 SG_ P31_d6_bit7 m49 : 55|1@1+ (1,0) [0|1] ""  PCM
 SG_ P39_d6_bit7 m57 : 55|1@1+ (1,0) [0|1] ""  PCM
 SG_ CHECKSUM : 56|4@1+ (1,0) [0|15] ""  PCM
 SG_ COUNTER : 60|2@1+ (1,0) [0|3] ""  PCM
 SG_ page_state : 62|2@1+ (1,0) [0|3] ""  PCM

CM_ BO_ 1089 "TX ACTIVE; DLC8; direction relative to PCM.";
BO_ 1089 XXX_0x441: 8 PCM
 SG_ BATID : 0|8@1+ (1,0) [0|255] ""  UNKNOWN
 SG_ unknown0 : 8|8@1+ (1,0) [0|255] ""  UNKNOWN
 SG_ unknown1 : 16|8@1+ (1,0) [0|255] ""  UNKNOWN
 SG_ unknown2 : 24|8@1+ (1,0) [0|255] ""  UNKNOWN
 SG_ unknown3 : 32|8@1+ (1,0) [0|255] ""  UNKNOWN
 SG_ unknown4 : 40|8@1+ (1,0) [0|255] ""  UNKNOWN
 SG_ unknown5 : 48|8@1+ (1,0) [0|255] ""  UNKNOWN
 SG_ CHECKSUM : 56|4@1+ (1,0) [0|15] ""  UNKNOWN
 SG_ COUNTER : 60|2@1+ (1,0) [0|3] ""  UNKNOWN
 SG_ unknown6 : 62|2@1+ (1,0) [0|3] ""  UNKNOWN

CM_ BO_ 1108 "TX ACTIVE; DLC8; direction relative to PCM.";
BO_ 1108 XXX_0x454: 8 PCM
 SG_ RETAINED_MODEL_QUANTITY_RAW : 0|8@1+ (1,0) [0|255] ""  UNKNOWN
 SG_ BARO_DISPLAY_CODE_RAW : 8|8@1+ (1,0) [0|255] ""  UNKNOWN
 SG_ STATE_CODE_B2_RAW : 16|4@1+ (1,0) [0|15] ""  UNKNOWN
 SG_ BAROMETRIC_SENSOR_FAULT_AGGREGAT : 20|1@1+ (1,0) [0|1] ""  UNKNOWN
 SG_ SIGNED_STATE_BIT5_RAW : 21|1@1+ (1,0) [0|1] ""  UNKNOWN
 SG_ MODEL_HOLD_ACTIVE_RAW : 22|1@1+ (1,0) [0|1] ""  UNKNOWN
 SG_ B2_BIT7_RAW : 23|1@1+ (1,0) [0|1] ""  UNKNOWN
 SG_ SCALED_MODEL_QUANTITY_RAW : 31|16@0+ (1,0) [0|65535] ""  UNKNOWN
 SG_ B5_RESERVED_RAW : 40|8@1+ (1,0) [0|255] ""  UNKNOWN
 SG_ ELECTRICAL_MONITOR_SECONDARY_RAW : 48|1@1+ (1,0) [0|1] ""  UNKNOWN
 SG_ STATUS_BIT_1_TBD : 49|1@1+ (1,0) [0|1] ""  UNKNOWN
 SG_ STATUS_BIT_2_TBD : 50|1@1+ (1,0) [0|1] ""  UNKNOWN
 SG_ ELECTRICAL_MONITOR_PRIMARY_RAW : 51|1@1+ (1,0) [0|1] ""  UNKNOWN
 SG_ B6_RESERVED_4_RAW : 52|1@1+ (1,0) [0|1] ""  UNKNOWN
 SG_ rsvd0 : 53|1@1+ (1,0) [0|1] ""  UNKNOWN
 SG_ rsvd1 : 54|1@1+ (1,0) [0|1] ""  UNKNOWN
 SG_ MONITOR_HOLD_RAW : 55|1@1+ (1,0) [0|1] ""  UNKNOWN
 SG_ CHECKSUM : 56|4@1+ (1,0) [0|15] ""  UNKNOWN
 SG_ COUNTER : 60|2@1+ (1,0) [0|3] ""  UNKNOWN
 SG_ B7_RESERVED_RAW : 62|2@1+ (1,0) [0|3] ""  UNKNOWN

CM_ BO_ 1125 "TX ACTIVE; DLC8; direction relative to PCM.";
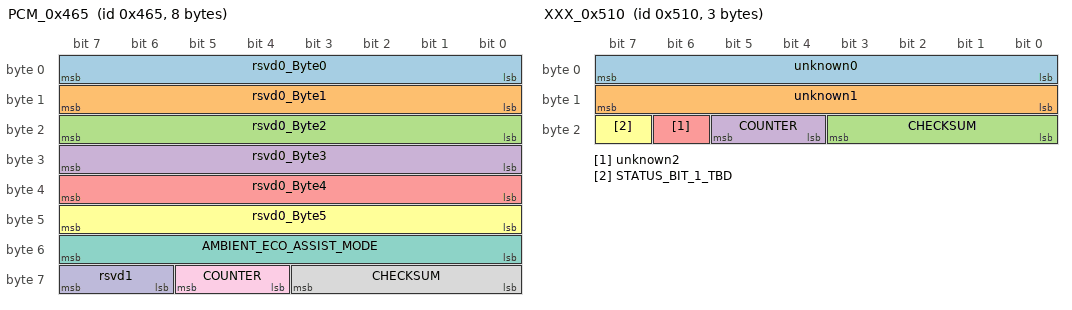
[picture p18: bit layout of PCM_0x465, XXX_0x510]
BO_ 1125 PCM_0x465: 8 PCM
 SG_ rsvd0_Byte0 : 0|8@1+ (1,0) [0|255] ""  UNKNOWN
 SG_ rsvd0_Byte1 : 8|8@1+ (1,0) [0|255] ""  UNKNOWN
 SG_ rsvd0_Byte2 : 16|8@1+ (1,0) [0|255] ""  UNKNOWN
 SG_ rsvd0_Byte3 : 24|8@1+ (1,0) [0|255] ""  UNKNOWN
 SG_ rsvd0_Byte4 : 32|8@1+ (1,0) [0|255] ""  UNKNOWN
 SG_ rsvd0_Byte5 : 40|8@1+ (1,0) [0|255] ""  UNKNOWN
 SG_ AMBIENT_ECO_ASSIST_MODE : 48|8@1+ (1,0) [0|255] ""  UNKNOWN
 SG_ CHECKSUM : 56|4@1+ (1,0) [0|15] ""  UNKNOWN
 SG_ COUNTER : 60|2@1+ (1,0) [0|3] ""  UNKNOWN
 SG_ rsvd1 : 62|2@1+ (1,0) [0|3] ""  UNKNOWN

CM_ BO_ 1296 "RX ACTIVE; DLC3; direction relative to PCM.";
BO_ 1296 XXX_0x510: 3 UNKNOWN
 SG_ unknown0 : 0|8@1+ (1,0) [0|255] ""  PCM
 SG_ unknown1 : 8|8@1+ (1,0) [0|255] ""  PCM
 SG_ CHECKSUM : 16|4@1+ (1,0) [0|15] ""  PCM
 SG_ COUNTER : 20|2@1+ (1,0) [0|3] ""  PCM
 SG_ unknown2 : 22|1@1+ (1,0) [0|1] ""  PCM
 SG_ STATUS_BIT_1_TBD : 23|1@1+ (1,0) [0|1] ""  PCM

CM_ BO_ 1365 "No saved selected registration; bus presence unproved; direction relative to PCM.";
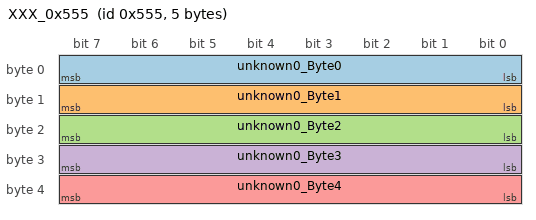
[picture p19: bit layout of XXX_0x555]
BO_ 1365 XXX_0x555: 5 UNKNOWN
 SG_ unknown0_Byte0 : 0|8@1+ (1,0) [0|255] ""  UNKNOWN
 SG_ unknown0_Byte1 : 8|8@1+ (1,0) [0|255] ""  UNKNOWN
 SG_ unknown0_Byte2 : 16|8@1+ (1,0) [0|255] ""  UNKNOWN
 SG_ unknown0_Byte3 : 24|8@1+ (1,0) [0|255] ""  UNKNOWN
 SG_ unknown0_Byte4 : 32|8@1+ (1,0) [0|255] ""  UNKNOWN

BA_DEF_ SG_  "ExactConversion" STRING ;
BA_DEF_ SG_  "SourceMembers" STRING ;
BA_DEF_ SG_  "DerivedUnit" STRING ;
BA_DEF_ SG_  "SystemSignalLongSymbol" STRING ;
BA_DEF_DEF_  "SystemSignalLongSymbol" "";
BA_ "SourceMembers" SG_ 145 CGLON2 "CGLON2_High2,CGLON2_Low8";
BA_ "SourceMembers" SG_ 145 CGLAT2 "CGLAT2_High4,CGLAT2_Low6";
BA_ "SourceMembers" SG_ 145 AuxiliaryCode "AuxiliaryCodeHigh6,AuxiliaryCodeLow2";
BA_ "SourceMembers" SG_ 145 CRYAW2 "CRYAW2_High8,CRYAW2_Low2";
BA_ "SourceMembers" SG_ 229 rsvd0 "STOCK_UNUSED_D3_HIGH2";
BA_ "SystemSignalLongSymbol" SG_ 316 FRAME_1AA_INVALID_OR_FALLBACK_ST "FRAME_1AA_INVALID_OR_FALLBACK_STATE_TBD";
BA_ "SourceMembers" SG_ 316 CLEPBCC "CLEPBCC_CAN_INVERTED";
BA_ "SourceMembers" SG_ 316 rsvd1 "STOCK_UNUSED_PEDAL_THRESHOLD_FLAG";
BA_ "SourceMembers" SG_ 316 APP "APP_RAW";
BA_ "SourceMembers" SG_ 344 STATUS_BIT_1_TBD "V6_STATUS_BIT7_TBD";
BA_ "SourceMembers" SG_ 344 DSTTRV "DSTTRV_LOW8";
BA_ "SourceMembers" SG_ 344 VNC "VNC_CAN_RAW";
BA_ "SourceMembers" SG_ 380 rsvd2 "STOCK_UNUSED_D6_LOW5";
BA_ "SourceMembers" SG_ 380 APP "APP_RAW";
BA_ "SourceMembers" SG_ 392 rsvd1 "STOCK_UNUSED_D5_BIT7";
BA_ "SystemSignalLongSymbol" SG_ 392 QUALIFIED_TRANSMISSION_STATUS_RA "QUALIFIED_TRANSMISSION_STATUS_RAW";
BA_ "SourceMembers" SG_ 392 ATPS "ATPS_RAW";
BA_ "SourceMembers" SG_ 392 ATP1 "AT1_SOURCE_RAW";
BA_ "SourceMembers" SG_ 392 ATP2_OR_ATPL "AT2_OR_ATL_SOURCE_RAW";
BA_ "SourceMembers" SG_ 392 ATPD3 "ATD3_SOURCE_RAW";
BA_ "SourceMembers" SG_ 392 rsvd0 "STOCK_UNUSED_D3_BIT4";
BA_ "SourceMembers" SG_ 392 ATPD "ATPD_RAW";
BA_ "SourceMembers" SG_ 392 ATPN "ATPN_RAW";
BA_ "SourceMembers" SG_ 392 ATPR "ATPR_RAW";
BA_ "SourceMembers" SG_ 392 ATPP "ATPP_RAW";
BA_ "SystemSignalLongSymbol" SG_ 392 TRANSMISSION_DIAGNOSTIC_LATCH_RA "TRANSMISSION_DIAGNOSTIC_LATCH_RAW";
BA_ "SourceMembers" SG_ 392 MIND "MIND_RAW";
BA_ "SourceMembers" SG_ 392 LEDA "LEDA_RAW";
BA_ "SourceMembers" SG_ 392 LEDB "LEDB_RAW";
BA_ "SourceMembers" SG_ 392 LEDC "LEDC_RAW";
BA_ "ExactConversion" SG_ 398 IEPSLD "0.5*floor(raw/5)";
BA_ "SourceMembers" SG_ 398 IEPSLD "IEPSLD_High2,IEPSLD_Low8";
BA_ "DerivedUnit" SG_ 398 IEPSLD "A";
BA_ "SourceMembers" SG_ 420 unknown3 "UnknownBits_2";
BA_ "ExactConversion" SG_ 420 MASTER_CYLINDER_PRESSURE_RAW "clamp(trunc0(2396*(raw-102)/100),0,65535)";
BA_ "SourceMembers" SG_ 420 MASTER_CYLINDER_PRESSURE_RAW "unknown1,PressureRaw12";
BA_ "DerivedUnit" SG_ 420 MASTER_CYLINDER_PRESSURE_RAW "receiver count; kPa unit association is L640-only";
BA_ "SourceMembers" SG_ 422 STATUS_BIT_3_TBD "SCM_STATUS_D7B6_TBD";
BA_ "SourceMembers" SG_ 422 unknown3 "UnknownBits_1";
BA_ "SourceMembers" SG_ 422 STATUS_BIT_1_TBD "V6_STATUS_D1_BITS5_4_TBD";
BA_ "SourceMembers" SG_ 422 CruiseControlButtons "ScmButton";
BA_ "SourceMembers" SG_ 432 STANDSTILL_STATUS_D5B0_TBD "unknown7";
BA_ "SourceMembers" SG_ 432 STANDSTILL_BRAKE_STATUS_D4B3_TBD "unknown6";
BA_ "SourceMembers" SG_ 432 unknown2 "UnknownBits_2";
BA_ "SourceMembers" SG_ 432 unknown1 "UnknownBits_1";
BA_ "SourceMembers" SG_ 464 CHECKSUM "HondaChecksumOnly";
BA_ "SourceMembers" SG_ 464 WheelSpeedRR "WheelSpeedRRHigh3,WheelSpeedRRMid8,WheelSpeedRRLow4";
BA_ "SourceMembers" SG_ 464 WheelSpeedRL "WheelSpeedRLHigh2,WheelSpeedRLMid8,WheelSpeedRLLow5";
BA_ "SourceMembers" SG_ 464 WheelSpeedFR "WheelSpeedFRHigh1,WheelSpeedFRMid8,WheelSpeedFRLow6";
BA_ "SourceMembers" SG_ 464 WheelSpeedFL "WheelSpeedFLHigh8,WheelSpeedFLLow7";
BA_ "SourceMembers" SG_ 476 STATUS_BIT_3_TBD "STATUS_B3_7_TBD";
BA_ "SourceMembers" SG_ 476 STATUS_BIT_2_TBD "STATUS_B3_6_RAW";
BA_ "SourceMembers" SG_ 476 STATUS_BIT_1_TBD "STATUS_B0_6_TBD";
BA_ "SystemSignalLongSymbol" SG_ 476 INTERNAL_MODE_OR_FEATURE_GATE_TB "INTERNAL_MODE_OR_FEATURE_GATE_TBD";
BA_ "SourceMembers" SG_ 490 ModelCode1 "LongAccel";
BA_ "SourceMembers" SG_ 490 ModelCode0 "LatAccel";
BA_ "SourceMembers" SG_ 493 rsvd1 "STOCK_UNUSED_D0_BITS5_4";
BA_ "SourceMembers" SG_ 493 STATUS_BIT_2_TBD "AUXILIARY_STATUS_BIT1_RAW";
BA_ "SourceMembers" SG_ 493 STATUS_BIT_1_TBD "AUXILIARY_STATUS_BIT0_RAW";
BA_ "SourceMembers" SG_ 493 rsvd0 "STOCK_UNUSED_D0_BIT1";
BA_ "SourceMembers" SG_ 538 unknown0_Byte4 "unknown0";
BA_ "SourceMembers" SG_ 538 unknown0_Byte3 "unknown0";
BA_ "SourceMembers" SG_ 538 unknown0_Byte2 "unknown0";
BA_ "SourceMembers" SG_ 538 unknown0_Byte1 "unknown0";
BA_ "SourceMembers" SG_ 538 unknown0_Byte0 "unknown0";
BA_ "SourceMembers" SG_ 542 unknown0_Byte6 "unknown0";
BA_ "SourceMembers" SG_ 542 unknown0_Byte5 "unknown0";
BA_ "SourceMembers" SG_ 542 unknown0_Byte4 "unknown0";
BA_ "SourceMembers" SG_ 542 unknown0_Byte3 "unknown0";
BA_ "SourceMembers" SG_ 542 unknown0_Byte2 "unknown0";
BA_ "SourceMembers" SG_ 542 unknown0_Byte1 "unknown0";
BA_ "SourceMembers" SG_ 542 unknown0_Byte0 "unknown0";
BA_ "SourceMembers" SG_ 545 ProtocolHighBits "PROTOCOL_FLAGS";
BA_ "SourceMembers" SG_ 660 unknown1 "UnknownBit_2";
BA_ "SourceMembers" SG_ 660 unknown0 "UnknownBits_1";
BA_ "SourceMembers" SG_ 661 COUNTER "X740_REFERENCE_COUNTER";
BA_ "SourceMembers" SG_ 661 CHECKSUM "X740_REFERENCE_CHECKSUM";
BA_ "SourceMembers" SG_ 661 unknown2 "UnknownBits_2";
BA_ "SourceMembers" SG_ 661 unknown1 "UnknownBits_1";
BA_ "SourceMembers" SG_ 773 unknown4 "UnknownBit_5";
BA_ "SourceMembers" SG_ 773 OCCUPANT_RESTRAINT_STATE_CODE_TB "DriverUnlatched,UnknownBit_3";
BA_ "SystemSignalLongSymbol" SG_ 773 OCCUPANT_RESTRAINT_STATE_CODE_TB "OCCUPANT_RESTRAINT_STATE_CODE_TBD";
BA_ "SourceMembers" SG_ 773 unknown2 "UnknownBit_4";
BA_ "SourceMembers" SG_ 773 unknown1 "UnknownBits_2";
BA_ "SourceMembers" SG_ 773 unknown0 "UnknownBits_1";
BA_ "SourceMembers" SG_ 777 SPEED_STATUS_D7B6_TBD "PROTOCOL_FLAGS";
BA_ "SourceMembers" SG_ 777 SECONDARY_SPEEDLIKE_WORD_RAW_TBD "unknown0,unknown1";
BA_ "SourceMembers" SG_ 800 STATUS_BIT_9_TBD "StatusB7_7_TBD";
BA_ "SourceMembers" SG_ 800 STATUS_BIT_8_TBD "StatusB7_6_TBD";
BA_ "SourceMembers" SG_ 800 COUNTER "RollingCounter";
BA_ "SourceMembers" SG_ 800 CHECKSUM "HondaChecksum";
BA_ "SourceMembers" SG_ 800 STATUS_BIT_7_TBD "StatusB6_3_TBD";
BA_ "SourceMembers" SG_ 800 STATUS_BIT_6_TBD "StatusB6_0_TBD";
BA_ "SystemSignalLongSymbol" SG_ 800 SignedCapOutOfDomainHighBitsB5_T "SignedCapOutOfDomainHighBitsB5_TBD";
BA_ "SourceMembers" SG_ 800 STATUS_BIT_5_TBD "StatusB4_7_TBD";
BA_ "SourceMembers" SG_ 800 rsvd4 "Reserved_012";
BA_ "SourceMembers" SG_ 800 rsvd3 "Reserved_010";
BA_ "SystemSignalLongSymbol" SG_ 800 SignedCapOutOfDomainSignBitB2_TB "SignedCapOutOfDomainSignBitB2_TBD";
BA_ "SourceMembers" SG_ 800 STATUS_BIT_4_TBD "StatusOrOutOfDomainCapBitB2_6_TBD";
BA_ "SystemSignalLongSymbol" SG_ 800 SignedCapOutOfDomainHighBitsB2_T "SignedCapOutOfDomainHighBitsB2_TBD";
BA_ "SourceMembers" SG_ 800 rsvd2 "Reserved_023";
BA_ "SourceMembers" SG_ 800 STATUS_BIT_3_TBD "StatusB1_6_TBD";
BA_ "SourceMembers" SG_ 800 rsvd1 "Reserved_004";
BA_ "SourceMembers" SG_ 800 STATUS_BIT_2_TBD "StatusB1_1_TBD";
BA_ "SourceMembers" SG_ 800 STATUS_BIT_1_TBD "StatusB1_0_TBD";
BA_ "SourceMembers" SG_ 800 rsvd0 "Reserved_002";
BA_ "SystemSignalLongSymbol" SG_ 804 DIAGNOSTIC_MONITOR_STATE_IN_0000 "DIAGNOSTIC_MONITOR_STATE_INVERTED_B7_TBD";
BA_ "SourceMembers" SG_ 804 rsvd0 "STOCK_UNUSED_B6_BIT6";
BA_ "SourceMembers" SG_ 804 IMMOBILIZER_REPORTING_CODE "CONTROL_ACTIVITY_CODE_RAW";
BA_ "SystemSignalLongSymbol" SG_ 804 DIAGNOSTIC_MONITOR_STATE_INVERTE "DIAGNOSTIC_MONITOR_STATE_INVERTED_B6_TBD";
BA_ "SystemSignalLongSymbol" SG_ 804 CRUISE_SET_SPEED_PRESENTATION_KP "CRUISE_SET_SPEED_PRESENTATION_KPH";
BA_ "SourceMembers" SG_ 804 IAT "IAT_RAW";
BA_ "SourceMembers" SG_ 804 ECT "ECT_RAW";
BA_ "SourceMembers" SG_ 808 rsvd8 "RESERVED_B7";
BA_ "SourceMembers" SG_ 808 rsvd7 "RESERVED_B6";
BA_ "SystemSignalLongSymbol" SG_ 808 CRUISE_TRANSITION_REASON_CODE_RA "CRUISE_TRANSITION_REASON_CODE_RAW";
BA_ "SystemSignalLongSymbol" SG_ 808 STARTUP_QUALIFICATION_COMPLETE_R "STARTUP_QUALIFICATION_COMPLETE_RAW";
BA_ "SourceMembers" SG_ 808 STATUS_BIT_1_TBD "STATUS_B5_2_TBD";
BA_ "SourceMembers" SG_ 808 rsvd4 "RESERVED_B4";
BA_ "SourceMembers" SG_ 808 rsvd3 "RESERVED_B3";
BA_ "SourceMembers" SG_ 808 rsvd2 "RESERVED_B2";
BA_ "SourceMembers" SG_ 808 rsvd1 "RESERVED_B1";
BA_ "SourceMembers" SG_ 808 rsvd0 "RESERVED_B0";
BA_ "SourceMembers" SG_ 871 VBPBAT "VBPBAT_RAW";
BA_ "ExactConversion" SG_ 871 IPBAT "clamp(trunc0((raw-2000000)/10),-32768,32767)*0.01";
BA_ "SourceMembers" SG_ 871 IPBAT "IPBAT_RAW";
BA_ "DerivedUnit" SG_ 871 IPBAT "A";
BA_ "SourceMembers" SG_ 882 BODY_STATUS_D1_B7_RAW "PROTOCOL_FLAGS";
BA_ "SourceMembers" SG_ 882 unknown1 "UnknownBits_2";
BA_ "SourceMembers" SG_ 882 BODY_STATUS_CODE_D0_RAW "UnknownBits_1";
BA_ "SourceMembers" SG_ 884 unknown0_Byte7 "unknown0";
BA_ "SourceMembers" SG_ 884 unknown0_Byte6 "unknown0";
BA_ "SourceMembers" SG_ 884 unknown0_Byte5 "unknown0";
BA_ "SourceMembers" SG_ 884 unknown0_Byte4 "unknown0";
BA_ "SourceMembers" SG_ 884 unknown0_Byte3 "unknown0";
BA_ "SourceMembers" SG_ 884 unknown0_Byte2 "unknown0";
BA_ "SourceMembers" SG_ 884 unknown0_Byte1 "unknown0";
BA_ "SourceMembers" SG_ 884 unknown0_Byte0 "unknown0";
BA_ "SourceMembers" SG_ 918 unknown0_Byte6 "unknown0";
BA_ "SourceMembers" SG_ 918 unknown0_Byte5 "unknown0";
BA_ "SourceMembers" SG_ 918 unknown0_Byte4 "unknown0";
BA_ "SourceMembers" SG_ 918 unknown0_Byte3 "unknown0";
BA_ "SourceMembers" SG_ 918 unknown0_Byte2 "unknown0";
BA_ "SourceMembers" SG_ 918 unknown0_Byte1 "unknown0";
BA_ "SourceMembers" SG_ 918 unknown0_Byte0 "unknown0";
BA_ "SourceMembers" SG_ 983 RetainedBankACodeWord2_Page1 "RetainedBankACodeWord2";
BA_ "SourceMembers" SG_ 983 RetainedBankACodeWord2_Page0 "RetainedBankACodeWord2";
BA_ "SourceMembers" SG_ 983 RetainedBankACodeWord1_Page1 "RetainedBankACodeWord1";
BA_ "SourceMembers" SG_ 983 RetainedBankACodeWord1_Page0 "RetainedBankACodeWord1";
BA_ "SourceMembers" SG_ 983 RetainedBankACodeWord0_Page1 "RetainedBankACodeWord0";
BA_ "SourceMembers" SG_ 983 RetainedBankACodeWord0_Page0 "RetainedBankACodeWord0";
BA_ "SourceMembers" SG_ 985 unknown0_Byte2 "unknown0";
BA_ "SourceMembers" SG_ 985 unknown0_Byte1 "unknown0";
BA_ "SourceMembers" SG_ 985 unknown0_Byte0 "unknown0";
BA_ "SourceMembers" SG_ 1024 COUNTER "RollingCounter";
BA_ "SourceMembers" SG_ 1024 CHECKSUM "HondaChecksum";
BA_ "SourceMembers" SG_ 1024 rsvd0 "Reserved";
BA_ "SourceMembers" SG_ 1027 rsvd2 "ReservedB4";
BA_ "SourceMembers" SG_ 1027 COUNTER "RollingCounter";
BA_ "SourceMembers" SG_ 1027 CHECKSUM "HondaChecksum";
BA_ "SourceMembers" SG_ 1027 STATUS_BIT_1_TBD "StatusB2_1_TBD";
BA_ "SourceMembers" SG_ 1029 IMMOBILIZER_LAMP_STATE_TBD "UnknownBits_2";
BA_ "SourceMembers" SG_ 1029 unknown4 "UnknownBits_1";
BA_ "SourceMembers" SG_ 1029 SHARED_431DC_STATUS_D2B3_TBD "unknown2";
BA_ "SourceMembers" SG_ 1029 REFERENCE_RX333_D0B2_NONZERO "unknown1";
BA_ "SourceMembers" SG_ 1029 MIL_DERIVED_STATUS "unknown0";
BA_ "SourceMembers" SG_ 1030 unknown0_Byte4 "unknown0";
BA_ "SourceMembers" SG_ 1030 unknown0_Byte3 "unknown0";
BA_ "SourceMembers" SG_ 1030 unknown0_Byte2 "unknown0";
BA_ "SourceMembers" SG_ 1030 unknown0_Byte1 "unknown0";
BA_ "SourceMembers" SG_ 1030 unknown0_Byte0 "unknown0";
BA_ "SourceMembers" SG_ 1036 DIAGNOSTIC_STATUS_FLAG7 "rsvd6,DIAGNOSTIC_STATUS_BIT7";
BA_ "SourceMembers" SG_ 1036 DIAGNOSTIC_STATUS_FLAG6 "rsvd6,DIAGNOSTIC_STATUS_BIT6";
BA_ "SourceMembers" SG_ 1036 P0F_ZERO_BYTE_B6_RAW "ZERO_BYTE_B6_RAW";
BA_ "SourceMembers" SG_ 1036 P0E_COMMANDEDEVAPORATIVEPURGE_B6 "COMMANDEDEVAPORATIVEPURGE_B6_RAW";
BA_ "SystemSignalLongSymbol" SG_ 1036 P0E_COMMANDEDEVAPORATIVEPURGE_B6 "P0E_COMMANDEDEVAPORATIVEPURGE_B6_RAW";
BA_ "SourceMembers" SG_ 1036 P0D_ZERO_BYTE_B6_RAW "ZERO_BYTE_B6_RAW";
BA_ "SourceMembers" SG_ 1036 P0A_LONGTERMFUELTRIMBANK1_B6_RAW "LONGTERMFUELTRIMBANK1_B6_RAW";
BA_ "SourceMembers" SG_ 1036 P07_APP_SENSOR_B_VOLTAGE_B6_RAW "APP_SENSOR_B_VOLTAGE_B6_RAW";
BA_ "SourceMembers" SG_ 1036 P06_BAROMETRICPRESSURE_B6_RAW "BAROMETRICPRESSURE_B6_RAW";
BA_ "SourceMembers" SG_ 1036 P05_ENGINECOOLANTTEMPERATURE_B6_ "ENGINECOOLANTTEMPERATURE_B6_RAW";
BA_ "SystemSignalLongSymbol" SG_ 1036 P05_ENGINECOOLANTTEMPERATURE_B6_ "P05_ENGINECOOLANTTEMPERATURE_B6_RAW";
BA_ "SourceMembers" SG_ 1036 P04_ZERO_BYTE_B6_RAW "ZERO_BYTE_B6_RAW";
BA_ "SourceMembers" SG_ 1036 P03_IDENTIFICATIONEXTRABYTE_RAW_ "IDENTIFICATIONEXTRABYTE_RAW_UNRESOLVED_B6_RAW";
BA_ "SystemSignalLongSymbol" SG_ 1036 P03_IDENTIFICATIONEXTRABYTE_RAW_ "P03_IDENTIFICATIONEXTRABYTE_RAW_UNRESOLVED_B6_RAW";
BA_ "SourceMembers" SG_ 1036 P02_VIN_CHARACTER12_B6_RAW "VIN_CHARACTER12_B6_RAW";
BA_ "SourceMembers" SG_ 1036 P01_VIN_CHARACTER6_B6_RAW "VIN_CHARACTER6_B6_RAW";
BA_ "SourceMembers" SG_ 1036 P00_ZERO_BYTE_B6_RAW "ZERO_BYTE_B6_RAW";
BA_ "SourceMembers" SG_ 1036 P0F_ZERO_BYTE_B5_RAW "ZERO_BYTE_B5_RAW";
BA_ "SourceMembers" SG_ 1036 P0D_ZERO_BYTE_B5_RAW "ZERO_BYTE_B5_RAW";
BA_ "SourceMembers" SG_ 1036 P0C_TOUT "TOUT,P0C_TOUT_RAW";
BA_ "SourceMembers" SG_ 1036 P0B_LAMBDA_B2 "LAMBDA_B2,P0B_LAMBDA_B2_RAW";
BA_ "SourceMembers" SG_ 1036 P0A_SHORTTERMFUELTRIMBANK1_B5_RA "SHORTTERMFUELTRIMBANK1_B5_RAW";
BA_ "SystemSignalLongSymbol" SG_ 1036 P0A_SHORTTERMFUELTRIMBANK1_B5_RA "P0A_SHORTTERMFUELTRIMBANK1_B5_RAW";
BA_ "SourceMembers" SG_ 1036 P09_THICMD "THICMD,P09_THICMD_RAW";
BA_ "SourceMembers" SG_ 1036 P08_RELTHW "RELTHW,P08_RELTHW_RAW";
BA_ "SourceMembers" SG_ 1036 P07_APP_SENSOR_A_VOLTAGE_B5_RAW "APP_SENSOR_A_VOLTAGE_B5_RAW";
BA_ "SourceMembers" SG_ 1036 P06_BARO_SENSOR_VOLTAGE_B5_RAW "BARO_SENSOR_VOLTAGE_B5_RAW";
BA_ "SourceMembers" SG_ 1036 P05_ECT_SENSOR_VOLTAGE_B5_RAW "ECT_SENSOR_VOLTAGE_B5_RAW";
BA_ "SourceMembers" SG_ 1036 P04_VARIANTCONFIGBYTE5_B5_RAW "VARIANTCONFIGBYTE5_B5_RAW";
BA_ "SourceMembers" SG_ 1036 P03_VIN_CHARACTER17_B5_RAW "VIN_CHARACTER17_B5_RAW";
BA_ "SourceMembers" SG_ 1036 P02_VIN_CHARACTER11_B5_RAW "VIN_CHARACTER11_B5_RAW";
BA_ "SourceMembers" SG_ 1036 P01_VIN_CHARACTER5_B5_RAW "VIN_CHARACTER5_B5_RAW";
BA_ "SourceMembers" SG_ 1036 P00_ZERO_BYTE_B5_RAW "ZERO_BYTE_B5_RAW";
BA_ "SourceMembers" SG_ 1036 P0F_ZERO_BYTE_B4_RAW "ZERO_BYTE_B4_RAW";
BA_ "SourceMembers" SG_ 1036 P0E_RUNTIMESINCEENGINESTART "RUNTIMESINCEENGINESTART_HIGH_B4_RAW,RUNTIMESINCEENGINESTART_LOW_B5_RAW";
BA_ "SourceMembers" SG_ 1036 P0D_AFM "AFM,P0D_AFM_RAW";
BA_ "SourceMembers" SG_ 1036 P0C_SVO2_B2 "SVO2_B2,P0C_SVO2_B2_RAW";
BA_ "SourceMembers" SG_ 1036 P09_LEARNEDBASELINEB_RAW_UNRESOL "LEARNEDBASELINEB_RAW_UNRESOLVED_B4_RAW";
BA_ "SystemSignalLongSymbol" SG_ 1036 P09_LEARNEDBASELINEB_RAW_UNRESOL "P09_LEARNEDBASELINEB_RAW_UNRESOLVED_B4_RAW";
BA_ "SourceMembers" SG_ 1036 P08_TH_2 "TH_2,P08_TH_2_RAW";
BA_ "SourceMembers" SG_ 1036 P07_CONTROL_MODULE_VOLTAGE_DECIV "CONTROL_MODULE_VOLTAGE_DECIVOLT_RAW";
BA_ "SystemSignalLongSymbol" SG_ 1036 P07_CONTROL_MODULE_VOLTAGE_DECIV "P07_CONTROL_MODULE_VOLTAGE_DECIVOLT_RAW";
BA_ "SourceMembers" SG_ 1036 P06_MANIFOLDABSOLUTEPRESSURE_B4_ "MANIFOLDABSOLUTEPRESSURE_B4_RAW";
BA_ "SystemSignalLongSymbol" SG_ 1036 P06_MANIFOLDABSOLUTEPRESSURE_B4_ "P06_MANIFOLDABSOLUTEPRESSURE_B4_RAW";
BA_ "SourceMembers" SG_ 1036 P05_RELATIVETHROTTLEPOSITION_B4_ "RELATIVETHROTTLEPOSITION_B4_RAW";
BA_ "SystemSignalLongSymbol" SG_ 1036 P05_RELATIVETHROTTLEPOSITION_B4_ "P05_RELATIVETHROTTLEPOSITION_B4_RAW";
BA_ "SourceMembers" SG_ 1036 P04_VARIANTCONFIGBYTE4_B4_RAW "VARIANTCONFIGBYTE4_B4_RAW";
BA_ "SourceMembers" SG_ 1036 P03_VIN_CHARACTER16_B4_RAW "VIN_CHARACTER16_B4_RAW";
BA_ "SourceMembers" SG_ 1036 P02_VIN_CHARACTER10_B4_RAW "VIN_CHARACTER10_B4_RAW";
BA_ "SourceMembers" SG_ 1036 P01_VIN_CHARACTER4_B4_RAW "VIN_CHARACTER4_B4_RAW";
BA_ "SourceMembers" SG_ 1036 P00_FORMAT_0X10_B4_RAW "FORMAT_0X10_B4_RAW";
BA_ "SourceMembers" SG_ 1036 P0F_ZERO_BYTE_B3_RAW "ZERO_BYTE_B3_RAW";
BA_ "SourceMembers" SG_ 1036 P0E_ZERO_BYTE_B3_RAW "ZERO_BYTE_B3_RAW";
BA_ "SourceMembers" SG_ 1036 P0D_ZERO_BYTE_B3_RAW "ZERO_BYTE_B3_RAW";
BA_ "SourceMembers" SG_ 1036 P0C_STATUS_BIT_1_TBD "STATUS_BIT_1_TBD,P0C_FUELSYSTEMSTATUSBYTEB_B3_RAW";
BA_ "SourceMembers" SG_ 1036 P0B_XILAF_B2 "XILAF_B2,P0B_XILAF_B2_RAW";
BA_ "SourceMembers" SG_ 1036 P0A_LAMBDA_B1 "LAMBDA_B1,P0A_LAMBDA_B1_RAW";
BA_ "SourceMembers" SG_ 1036 P09_LEARNEDBASELINEA_RAW_UNRESOL "LEARNEDBASELINEA_RAW_UNRESOLVED_B3_RAW";
BA_ "SystemSignalLongSymbol" SG_ 1036 P09_LEARNEDBASELINEA_RAW_UNRESOL "P09_LEARNEDBASELINEA_RAW_UNRESOLVED_B3_RAW";
BA_ "SourceMembers" SG_ 1036 P08_TH_1 "TH_1,P08_TH_1_RAW";
BA_ "SourceMembers" SG_ 1036 P07_IG "IG";
BA_ "SourceMembers" SG_ 1036 P06_MAP_SENSOR_VOLTAGE_B3_RAW "MAP_SENSOR_VOLTAGE_B3_RAW";
BA_ "SourceMembers" SG_ 1036 P05_THROTTLEPOSITION_B3_RAW "THROTTLEPOSITION_B3_RAW";
BA_ "SourceMembers" SG_ 1036 P04_VARIANTCONFIGBYTE3_B3_RAW "VARIANTCONFIGBYTE3_B3_RAW";
BA_ "SourceMembers" SG_ 1036 P03_VIN_CHARACTER15_B3_RAW "VIN_CHARACTER15_B3_RAW";
BA_ "SourceMembers" SG_ 1036 P02_VIN_CHARACTER9_B3_RAW "VIN_CHARACTER9_B3_RAW";
BA_ "SourceMembers" SG_ 1036 P01_VIN_CHARACTER3_B3_RAW "VIN_CHARACTER3_B3_RAW";
BA_ "SourceMembers" SG_ 1036 P0F_ZERO_BYTE_B2_RAW "ZERO_BYTE_B2_RAW";
BA_ "SourceMembers" SG_ 1036 P0D_ZERO_BYTE_B2_RAW "ZERO_BYTE_B2_RAW";
BA_ "SourceMembers" SG_ 1036 P0C_KLAFAVE_B2 "KLAFAVE_B2,P0C_KLAFAVE_B2_RAW";
BA_ "SourceMembers" SG_ 1036 P0B_SVO2_B1 "SVO2_B1,P0B_SVO2_B1_RAW";
BA_ "SourceMembers" SG_ 1036 P07_CALCULATEDENGINELOAD_B2_RAW "CALCULATEDENGINELOAD_B2_RAW";
BA_ "SourceMembers" SG_ 1036 P06_INTAKEAIRTEMPERATURE_B2_RAW "INTAKEAIRTEMPERATURE_B2_RAW";
BA_ "SourceMembers" SG_ 1036 P04_VARIANTCONFIGBYTE2_B2_RAW "VARIANTCONFIGBYTE2_B2_RAW";
BA_ "SourceMembers" SG_ 1036 P03_VIN_CHARACTER14_B2_RAW "VIN_CHARACTER14_B2_RAW";
BA_ "SourceMembers" SG_ 1036 P02_VIN_CHARACTER8_B2_RAW "VIN_CHARACTER8_B2_RAW";
BA_ "SourceMembers" SG_ 1036 P01_VIN_CHARACTER2_B2_RAW "VIN_CHARACTER2_B2_RAW";
BA_ "SourceMembers" SG_ 1036 P00_DIAGNOSTIC_EVENT_CACHE_WORD "DIAGNOSTIC_EVENT_CACHE_WORD_HIGH_B2_RAW,DIAGNOSTIC_EVENT_CACHE_WORD_LOW_B3_RAW";
BA_ "SourceMembers" SG_ 1036 P0F_FUELTANKLEVELINPUT_B1_RAW "FUELTANKLEVELINPUT_B1_RAW";
BA_ "SourceMembers" SG_ 1036 P0E_MASSAIRFLOW "MASSAIRFLOW_HIGH_B1_RAW,MASSAIRFLOW_LOW_B2_RAW";
BA_ "SourceMembers" SG_ 1036 P0D_LIFT "LIFT,P0D_LIFT_RAW";
BA_ "SourceMembers" SG_ 1036 P0C_KLAF_B2 "KLAF_B2,P0C_KLAF_B2_RAW";
BA_ "SourceMembers" SG_ 1036 P0B_STATUS_BIT_1_TBD "STATUS_BIT_1_TBD,P0B_FUELSYSTEMSTATUSBYTEA_B1_RAW";
BA_ "SourceMembers" SG_ 1036 P0A_XILAF_B1 "XILAF_B1,P0A_XILAF_B1_RAW";
BA_ "SourceMembers" SG_ 1036 P09_THO "THO,P09_THO_RAW";
BA_ "SourceMembers" SG_ 1036 P08_APP "APP,P08_APP_RAW";
BA_ "SourceMembers" SG_ 1036 P07_VEHICLESPEED_B1_RAW "VEHICLESPEED_B1_RAW";
BA_ "SourceMembers" SG_ 1036 P06_IAT_SENSOR_VOLTAGE_B1_RAW "IAT_SENSOR_VOLTAGE_B1_RAW";
BA_ "SourceMembers" SG_ 1036 P05_NE "ENGINERPM_HIGH_B1_RAW,ENGINERPM_LOW_B2_RAW";
BA_ "SourceMembers" SG_ 1036 P04_VARIANTCONFIGBYTE1_B1_RAW "VARIANTCONFIGBYTE1_B1_RAW";
BA_ "SourceMembers" SG_ 1036 P03_VIN_CHARACTER13_B1_RAW "VIN_CHARACTER13_B1_RAW";
BA_ "SourceMembers" SG_ 1036 P02_VIN_CHARACTER7_B1_RAW "VIN_CHARACTER7_B1_RAW";
BA_ "SourceMembers" SG_ 1036 P01_VIN_CHARACTER1_B1_RAW "VIN_CHARACTER1_B1_RAW";
BA_ "SourceMembers" SG_ 1036 P00_ZERO_BYTE_B1_RAW "ZERO_BYTE_B1_RAW";
BA_ "SourceMembers" SG_ 1039 P07_OP2SW "OP2SW";
BA_ "SourceMembers" SG_ 1039 P07_OP3SW "OP3SW";
BA_ "SourceMembers" SG_ 1039 P07_OP4SW "OP4SW";
BA_ "SourceMembers" SG_ 1039 P07_OP5SW "OP5SW";
BA_ "SourceMembers" SG_ 1039 P07_OP6SW "OP6SW";
BA_ "SourceMembers" SG_ 1039 P07_OPSWA "OPSWA";
BA_ "SourceMembers" SG_ 1039 P07_OPSWB "OPSWB";
BA_ "SourceMembers" SG_ 1039 UnspecifiedPage_rsvd5 "rsvd5";
BA_ "SourceMembers" SG_ 1039 P07_OPPLSW "OPPLSW";
BA_ "SourceMembers" SG_ 1039 P06_VSP "VSP";
BA_ "SourceMembers" SG_ 1039 P05_ICMDA "ICMDA";
BA_ "SourceMembers" SG_ 1039 P03_PB "PB";
BA_ "SourceMembers" SG_ 1039 P02_TWAD "TWAD";
BA_ "SourceMembers" SG_ 1039 P01_CONFIG_BYTE6_RAW "CONFIG_BYTE6_RAW";
BA_ "SourceMembers" SG_ 1039 UnspecifiedPage_rsvd4 "rsvd4";
BA_ "SourceMembers" SG_ 1039 P07_ICMDD "ICMDD";
BA_ "SourceMembers" SG_ 1039 P06_IACTC "IACTC";
BA_ "SourceMembers" SG_ 1039 P05_APS2AD "APS2AD";
BA_ "SourceMembers" SG_ 1039 P04_NCW "NCW";
BA_ "SourceMembers" SG_ 1039 P03_PBAD "PBAD";
BA_ "SourceMembers" SG_ 1039 P02_RELTH "RELTH";
BA_ "SourceMembers" SG_ 1039 P01_CONFIG_BYTE5_RAW "CONFIG_BYTE5_RAW";
BA_ "SourceMembers" SG_ 1039 P00_PAGE0_RESERVED_RAW "PAGE0_RESERVED_RAW";
BA_ "SourceMembers" SG_ 1039 UnspecifiedPage_rsvd3 "rsvd3";
BA_ "SourceMembers" SG_ 1039 P07_IACTD "IACTD";
BA_ "SourceMembers" SG_ 1039 P06_ICMDC "ICMDC";
BA_ "SourceMembers" SG_ 1039 P05_APS1AD "APS1AD";
BA_ "SourceMembers" SG_ 1039 P03_STATUS_RAW "STATUS_RAW";
BA_ "SourceMembers" SG_ 1039 P02_THAD1 "THAD1";
BA_ "SourceMembers" SG_ 1039 P01_CONFIG_BYTE4_RAW "CONFIG_BYTE4_RAW";
BA_ "SourceMembers" SG_ 1039 P00_PAGE0_LENGTH_RAW "PAGE0_LENGTH_RAW";
BA_ "SourceMembers" SG_ 1039 UnspecifiedPage_rsvd2 "rsvd2";
BA_ "SourceMembers" SG_ 1039 P07_TATF "TATF";
BA_ "SourceMembers" SG_ 1039 P06_IACTB "IACTB";
BA_ "SourceMembers" SG_ 1039 P05_APSAT "APSAT";
BA_ "SourceMembers" SG_ 1039 P04_NEW "NEW";
BA_ "SourceMembers" SG_ 1039 P03_SO "SO";
BA_ "SourceMembers" SG_ 1039 P02_VNM "VNM";
BA_ "SourceMembers" SG_ 1039 P01_CONFIG_BYTE3_RAW "CONFIG_BYTE3_RAW";
BA_ "SourceMembers" SG_ 1039 UnspecifiedPage_rsvd1 "rsvd1";
BA_ "SourceMembers" SG_ 1039 P07_TATFAD "TATFAD";
BA_ "SourceMembers" SG_ 1039 P06_ICMDB "ICMDB";
BA_ "SourceMembers" SG_ 1039 P04_PA "PA";
BA_ "SourceMembers" SG_ 1039 P03_VB "VB";
BA_ "SourceMembers" SG_ 1039 P02_VNC "VNC";
BA_ "SourceMembers" SG_ 1039 P01_CONFIG_BYTE2_RAW "CONFIG_BYTE2_RAW";
BA_ "SourceMembers" SG_ 1039 P00_PAGE0_EVENT_RAW "PAGE0_EVENT_RAW";
BA_ "SourceMembers" SG_ 1039 P07_SHA "SHA";
BA_ "SourceMembers" SG_ 1039 P07_SHB "SHB";
BA_ "SourceMembers" SG_ 1039 P07_SHC "SHC";
BA_ "SourceMembers" SG_ 1039 P07_SHD "SHD";
BA_ "SourceMembers" SG_ 1039 P07_SHE "SHE";
BA_ "SourceMembers" SG_ 1039 P07_SHF "SHF";
BA_ "SourceMembers" SG_ 1039 P07_SHG "SHG";
BA_ "SourceMembers" SG_ 1039 UnspecifiedPage_rsvd0 "rsvd0";
BA_ "SourceMembers" SG_ 1039 P07_PLA "PLA";
BA_ "SourceMembers" SG_ 1039 P06_IACTA "IACTA";
BA_ "SourceMembers" SG_ 1039 P05_NMW "NMW";
BA_ "SourceMembers" SG_ 1039 P04_PAAD "PAAD";
BA_ "SourceMembers" SG_ 1039 P03_TW "TW";
BA_ "SourceMembers" SG_ 1039 P02_NEW "NEW";
BA_ "SourceMembers" SG_ 1039 P01_CONFIG_BYTE1_RAW "CONFIG_BYTE1_RAW";
BA_ "SourceMembers" SG_ 1039 P00_PAGE0_FORMAT_RAW "PAGE0_FORMAT_RAW";
BA_ "SourceMembers" SG_ 1057 COUNTER "counter_2bit";
BA_ "SourceMembers" SG_ 1057 CHECKSUM "checksum_nibble";
BA_ "SourceMembers" SG_ 1064 SecondaryDistanceCounterRaw_0001 "SecondaryDistanceCounterRawTBD";
BA_ "SystemSignalLongSymbol" SG_ 1064 SecondaryDistanceCounterRaw_0001 "SecondaryDistanceCounterRawTBD_Byte2";
BA_ "SourceMembers" SG_ 1064 SecondaryDistanceCounterRaw_0000 "SecondaryDistanceCounterRawTBD";
BA_ "SystemSignalLongSymbol" SG_ 1064 SecondaryDistanceCounterRaw_0000 "SecondaryDistanceCounterRawTBD_Byte1";
BA_ "SourceMembers" SG_ 1064 SecondaryDistanceCounterRawTBD_B "SecondaryDistanceCounterRawTBD";
BA_ "SystemSignalLongSymbol" SG_ 1064 SecondaryDistanceCounterRawTBD_B "SecondaryDistanceCounterRawTBD_Byte0";
BA_ "SourceMembers" SG_ 1088 P39_d6_bit7 "d6_bit7";
BA_ "SourceMembers" SG_ 1088 P31_d6_bit7 "d6_bit7";
BA_ "SourceMembers" SG_ 1088 P31_d6_bit6 "d6_bit6";
BA_ "SourceMembers" SG_ 1088 P39_unknown2 "unknown2";
BA_ "SourceMembers" SG_ 1088 P39_d6_bit3 "d6_bit3";
BA_ "SourceMembers" SG_ 1088 P31_unknown3 "unknown3";
BA_ "SourceMembers" SG_ 1088 P39_d6_bit2 "d6_bit2";
BA_ "SourceMembers" SG_ 1088 P39_BDCHGBAT "BDCHGBAT";
BA_ "SourceMembers" SG_ 1088 UnspecifiedPage_unknown5 "unknown5";
BA_ "SourceMembers" SG_ 1088 P3A_unknown2 "unknown2";
BA_ "SourceMembers" SG_ 1088 P39_BATSRST "BATSRST";
BA_ "SourceMembers" SG_ 1088 P33_unknown5 "unknown5";
BA_ "SourceMembers" SG_ 1088 P31_d6_low3 "d6_low3";
BA_ "SourceMembers" SG_ 1088 P31_unknown2 "unknown2";
BA_ "SourceMembers" SG_ 1088 P31_d5_bit6 "d5_bit6";
BA_ "SourceMembers" SG_ 1088 P31_d5_bit5 "d5_bit5";
BA_ "SourceMembers" SG_ 1088 P31_d5_mid2 "d5_mid2";
BA_ "SourceMembers" SG_ 1088 UnspecifiedPage_unknown4 "unknown4";
BA_ "SourceMembers" SG_ 1088 P3A_unknown1 "unknown1";
BA_ "SourceMembers" SG_ 1088 P39_SOFVPBAT "SOFVPBAT,P39_SOFVPBAT_RAW";
BA_ "SourceMembers" SG_ 1088 P33_unknown4 "unknown4";
BA_ "SourceMembers" SG_ 1088 P32_raw56 "raw56";
BA_ "SourceMembers" SG_ 1088 P31_d5_low3 "d5_low3";
BA_ "SourceMembers" SG_ 1088 UnspecifiedPage_unknown3 "unknown3";
BA_ "SourceMembers" SG_ 1088 P39_SOHQPBAT "SOHQPBAT,P39_SOHQPBAT_RAW";
BA_ "SourceMembers" SG_ 1088 P33_unknown3 "unknown3";
BA_ "SourceMembers" SG_ 1088 P31_SOCPBAT "SOCPBAT,P31_SOCPBAT_RAW";
BA_ "SourceMembers" SG_ 1088 UnspecifiedPage_unknown2 "unknown2";
BA_ "SourceMembers" SG_ 1088 P3A_page3A_word34 "page3A_word34";
BA_ "SourceMembers" SG_ 1088 P39_VBATCO "VBATCO,P39_VBATCO_RAW";
BA_ "SourceMembers" SG_ 1088 P33_unknown2 "unknown2";
BA_ "SourceMembers" SG_ 1088 P32_raw34 "raw34";
BA_ "SourceMembers" SG_ 1088 P31_TPBAT "TPBAT,P31_TPBAT_RAW";
BA_ "SourceMembers" SG_ 1088 UnspecifiedPage_unknown1 "unknown1";
BA_ "SourceMembers" SG_ 1088 P3A_unknown0 "unknown0";
BA_ "SourceMembers" SG_ 1088 P39_unknown1 "unknown1";
BA_ "SourceMembers" SG_ 1088 P33_unknown1 "unknown1";
BA_ "SourceMembers" SG_ 1088 P31_unknown1 "unknown1";
BA_ "SourceMembers" SG_ 1088 UnspecifiedPage_unknown0 "unknown0";
BA_ "SourceMembers" SG_ 1088 P3A_page3A_temp_word_RAW "page3A_temp_word_RAW";
BA_ "SourceMembers" SG_ 1088 P39_unknown0 "unknown0";
BA_ "SourceMembers" SG_ 1088 P33_unknown0 "unknown0";
BA_ "ExactConversion" SG_ 1088 P32_RCLPBAT "min(floor(min(raw,32767)/10),255)*0.1";
BA_ "SourceMembers" SG_ 1088 P32_RCLPBAT "RCLPBAT,P32_RCLPBAT_RAW";
BA_ "DerivedUnit" SG_ 1088 P32_RCLPBAT "mOhm";
BA_ "SourceMembers" SG_ 1088 P31_unknown0 "unknown0";
BA_ "SourceMembers" SG_ 1089 unknown6 "Reserved";
BA_ "SourceMembers" SG_ 1089 COUNTER "RollingCounter";
BA_ "SourceMembers" SG_ 1089 CHECKSUM "HondaChecksum";
BA_ "SourceMembers" SG_ 1089 unknown5 "RawBankByte6_TBD";
BA_ "SourceMembers" SG_ 1089 unknown4 "RawBankByte5_TBD";
BA_ "SourceMembers" SG_ 1089 unknown3 "RawBankByte4_TBD";
BA_ "SourceMembers" SG_ 1089 unknown2 "RawBankByte3_TBD";
BA_ "SourceMembers" SG_ 1089 unknown1 "RawBankByte2_TBD";
BA_ "SourceMembers" SG_ 1089 unknown0 "RawBankByte1_TBD";
BA_ "SourceMembers" SG_ 1108 rsvd1 "STOCK_UNUSED_B6_BIT6";
BA_ "SourceMembers" SG_ 1108 rsvd0 "STOCK_UNUSED_B6_BIT5";
BA_ "SourceMembers" SG_ 1108 STATUS_BIT_2_TBD "STATUS_B6_2_RAW";
BA_ "SourceMembers" SG_ 1108 STATUS_BIT_1_TBD "STATUS_B6_1_RAW";
BA_ "SystemSignalLongSymbol" SG_ 1108 BAROMETRIC_SENSOR_FAULT_AGGREGAT "BAROMETRIC_SENSOR_FAULT_AGGREGATE";
BA_ "SourceMembers" SG_ 1125 COUNTER "RollingCounter";
BA_ "SourceMembers" SG_ 1125 CHECKSUM "HondaChecksum";
BA_ "SourceMembers" SG_ 1125 rsvd0_Byte5 "rsvd0";
BA_ "SourceMembers" SG_ 1125 rsvd0_Byte4 "rsvd0";
BA_ "SourceMembers" SG_ 1125 rsvd0_Byte3 "rsvd0";
BA_ "SourceMembers" SG_ 1125 rsvd0_Byte2 "rsvd0";
BA_ "SourceMembers" SG_ 1125 rsvd0_Byte1 "rsvd0";
BA_ "SourceMembers" SG_ 1125 rsvd0_Byte0 "rsvd0";
BA_ "SourceMembers" SG_ 1296 STATUS_BIT_1_TBD "SingleBitStatusD2Bit7TBD";
BA_ "SourceMembers" SG_ 1365 unknown0_Byte4 "unknown0";
BA_ "SourceMembers" SG_ 1365 unknown0_Byte3 "unknown0";
BA_ "SourceMembers" SG_ 1365 unknown0_Byte2 "unknown0";
BA_ "SourceMembers" SG_ 1365 unknown0_Byte1 "unknown0";
BA_ "SourceMembers" SG_ 1365 unknown0_Byte0 "unknown0";
VAL_ 145 ScalarNotReady 1 "not ready" ;
VAL_ 316 CLEPBCC 0 "ON" 1 "OFF" ;
VAL_ 316 TORQUE_STATE 0 "Normal" 1 "VsaControlCandidate" 2 "FuelCut" 3 "Unknown" ;
VAL_ 380 BKSWNC 0 "CLOSE" 1 "OPEN" ;
VAL_ 380 CRPL 0 "OFF" 1 "ON" ;
VAL_ 380 MILSTAT 0 "OFF" 1 "ON" ;
VAL_ 380 WARN 0 "OFF" 1 "ON" ;
VAL_ 380 BKSW 0 "OFF" 1 "ON" ;
VAL_ 392 ATPS 0 "OFF" 1 "ON" ;
VAL_ 392 ATP1 0 "OFF" 1 "ON" ;
VAL_ 392 ATPD3 0 "OFF" 1 "ON" ;
VAL_ 392 ATPD 0 "OFF" 1 "ON" ;
VAL_ 392 ATPN 0 "OFF" 1 "ON" ;
VAL_ 392 ATPR 0 "OFF" 1 "ON" ;
VAL_ 392 ATPP 0 "OFF" 1 "ON" ;
VAL_ 392 MIND 0 "OFF" 1 "ON" ;
VAL_ 392 LEDA 0 "OFF" 1 "ON" ;
VAL_ 392 LEDB 0 "OFF" 1 "ON" ;
VAL_ 392 LEDC 0 "OFF" 1 "ON" ;
VAL_ 420 VSACASEN 0 "Normal" 1 "INHIBITED" ;
VAL_ 476 FCAPOPEN 0 "CLOSE" 1 "OPEN" ;
VAL_ 545 ECONO 0 "Off" 3 "On" ;
VAL_ 804 IMMOBILIZER_REPORTING_CODE 0 "CompleteAccepted" 1 "Incomplete" 2 "CompleteNotAccepted" ;
VAL_ 804 SCS 0 "OPEN" 1 "SHORT" ;
VAL_ 804 IAT 255 "invalid" ;
VAL_ 804 ECT 255 "invalid" ;
VAL_ 871 IBATSTATUS 0 "Normal condition" 1 "Circuit open failure" ;
VAL_ 983 PageIndex 0 "Slots0To2" 1 "Slots3To5" ;
VAL_ 1024 MILSTAT 0 "OFF" 1 "ON" ;
VAL_ 1039 P07_OP2SW 0 "OFF" 1 "ON" ;
VAL_ 1039 P07_OP3SW 0 "OFF" 1 "ON" ;
VAL_ 1039 P07_OP4SW 0 "OFF" 1 "ON" ;
VAL_ 1039 P07_OP5SW 0 "OFF" 1 "ON" ;
VAL_ 1039 P07_OP6SW 0 "OFF" 1 "ON" ;
VAL_ 1039 P07_OPSWA 0 "OFF" 1 "ON" ;
VAL_ 1039 P07_OPSWB 0 "OFF" 1 "ON" ;
VAL_ 1039 P07_OPPLSW 0 "OFF" 1 "ON" ;
VAL_ 1039 P07_SHA 0 "OFF" 1 "ON" ;
VAL_ 1039 P07_SHB 0 "OFF" 1 "ON" ;
VAL_ 1039 P07_SHC 0 "OFF" 1 "ON" ;
VAL_ 1039 P07_SHD 0 "OFF" 1 "ON" ;
VAL_ 1039 P07_SHE 0 "OFF" 1 "ON" ;
VAL_ 1039 P07_SHF 0 "OFF" 1 "ON" ;
VAL_ 1039 P07_SHG 0 "OFF" 1 "ON" ;
VAL_ 1039 P07_PLA 0 "OFF" 1 "ON" ;
VAL_ 1125 AMBIENT_ECO_ASSIST_MODE 1 "White" 2 "LightGreen" 3 "Green" ;

SG_MUL_VAL_ 983 RetainedBankACodeWord0_Page0 PageIndex 0-0;
SG_MUL_VAL_ 983 RetainedBankACodeWord0_Page1 PageIndex 1-1;
SG_MUL_VAL_ 983 RetainedBankACodeWord1_Page0 PageIndex 0-0;
SG_MUL_VAL_ 983 RetainedBankACodeWord1_Page1 PageIndex 1-1;
SG_MUL_VAL_ 983 RetainedBankACodeWord2_Page0 PageIndex 0-0;
SG_MUL_VAL_ 983 RetainedBankACodeWord2_Page1 PageIndex 1-1;
SG_MUL_VAL_ 1036 P00_ZERO_BYTE_B1_RAW MULTIPLEX_PAGE 0-0;
SG_MUL_VAL_ 1036 P01_VIN_CHARACTER1_B1_RAW MULTIPLEX_PAGE 1-1;
SG_MUL_VAL_ 1036 P02_VIN_CHARACTER7_B1_RAW MULTIPLEX_PAGE 2-2;
SG_MUL_VAL_ 1036 P03_VIN_CHARACTER13_B1_RAW MULTIPLEX_PAGE 3-3;
SG_MUL_VAL_ 1036 P04_VARIANTCONFIGBYTE1_B1_RAW MULTIPLEX_PAGE 4-4;
SG_MUL_VAL_ 1036 P05_NE MULTIPLEX_PAGE 5-5;
SG_MUL_VAL_ 1036 P06_IAT_SENSOR_VOLTAGE_B1_RAW MULTIPLEX_PAGE 6-6;
SG_MUL_VAL_ 1036 P07_VEHICLESPEED_B1_RAW MULTIPLEX_PAGE 7-7;
SG_MUL_VAL_ 1036 P08_APP MULTIPLEX_PAGE 8-8;
SG_MUL_VAL_ 1036 P09_THO MULTIPLEX_PAGE 9-9;
SG_MUL_VAL_ 1036 P0A_XILAF_B1 MULTIPLEX_PAGE 10-10;
SG_MUL_VAL_ 1036 P0B_STATUS_BIT_1_TBD MULTIPLEX_PAGE 11-11;
SG_MUL_VAL_ 1036 P0C_KLAF_B2 MULTIPLEX_PAGE 12-12;
SG_MUL_VAL_ 1036 P0D_LIFT MULTIPLEX_PAGE 13-13;
SG_MUL_VAL_ 1036 P0E_MASSAIRFLOW MULTIPLEX_PAGE 14-14;
SG_MUL_VAL_ 1036 P0F_FUELTANKLEVELINPUT_B1_RAW MULTIPLEX_PAGE 15-15;
SG_MUL_VAL_ 1036 P00_DIAGNOSTIC_EVENT_CACHE_WORD MULTIPLEX_PAGE 0-0;
SG_MUL_VAL_ 1036 P01_VIN_CHARACTER2_B2_RAW MULTIPLEX_PAGE 1-1;
SG_MUL_VAL_ 1036 P02_VIN_CHARACTER8_B2_RAW MULTIPLEX_PAGE 2-2;
SG_MUL_VAL_ 1036 P03_VIN_CHARACTER14_B2_RAW MULTIPLEX_PAGE 3-3;
SG_MUL_VAL_ 1036 P04_VARIANTCONFIGBYTE2_B2_RAW MULTIPLEX_PAGE 4-4;
SG_MUL_VAL_ 1036 P06_INTAKEAIRTEMPERATURE_B2_RAW MULTIPLEX_PAGE 6-6;
SG_MUL_VAL_ 1036 P07_CALCULATEDENGINELOAD_B2_RAW MULTIPLEX_PAGE 7-7;
SG_MUL_VAL_ 1036 P0B_SVO2_B1 MULTIPLEX_PAGE 11-11;
SG_MUL_VAL_ 1036 P0C_KLAFAVE_B2 MULTIPLEX_PAGE 12-12;
SG_MUL_VAL_ 1036 P0D_ZERO_BYTE_B2_RAW MULTIPLEX_PAGE 13-13;
SG_MUL_VAL_ 1036 P0F_ZERO_BYTE_B2_RAW MULTIPLEX_PAGE 15-15;
SG_MUL_VAL_ 1036 P01_VIN_CHARACTER3_B3_RAW MULTIPLEX_PAGE 1-1;
SG_MUL_VAL_ 1036 P02_VIN_CHARACTER9_B3_RAW MULTIPLEX_PAGE 2-2;
SG_MUL_VAL_ 1036 P03_VIN_CHARACTER15_B3_RAW MULTIPLEX_PAGE 3-3;
SG_MUL_VAL_ 1036 P04_VARIANTCONFIGBYTE3_B3_RAW MULTIPLEX_PAGE 4-4;
SG_MUL_VAL_ 1036 P05_THROTTLEPOSITION_B3_RAW MULTIPLEX_PAGE 5-5;
SG_MUL_VAL_ 1036 P06_MAP_SENSOR_VOLTAGE_B3_RAW MULTIPLEX_PAGE 6-6;
SG_MUL_VAL_ 1036 P07_IG MULTIPLEX_PAGE 7-7;
SG_MUL_VAL_ 1036 P08_TH_1 MULTIPLEX_PAGE 8-8;
SG_MUL_VAL_ 1036 P09_LEARNEDBASELINEA_RAW_UNRESOL MULTIPLEX_PAGE 9-9;
SG_MUL_VAL_ 1036 P0A_LAMBDA_B1 MULTIPLEX_PAGE 10-10;
SG_MUL_VAL_ 1036 P0B_XILAF_B2 MULTIPLEX_PAGE 11-11;
SG_MUL_VAL_ 1036 P0C_STATUS_BIT_1_TBD MULTIPLEX_PAGE 12-12;
SG_MUL_VAL_ 1036 P0D_ZERO_BYTE_B3_RAW MULTIPLEX_PAGE 13-13;
SG_MUL_VAL_ 1036 P0E_ZERO_BYTE_B3_RAW MULTIPLEX_PAGE 14-14;
SG_MUL_VAL_ 1036 P0F_ZERO_BYTE_B3_RAW MULTIPLEX_PAGE 15-15;
SG_MUL_VAL_ 1036 P00_FORMAT_0X10_B4_RAW MULTIPLEX_PAGE 0-0;
SG_MUL_VAL_ 1036 P01_VIN_CHARACTER4_B4_RAW MULTIPLEX_PAGE 1-1;
SG_MUL_VAL_ 1036 P02_VIN_CHARACTER10_B4_RAW MULTIPLEX_PAGE 2-2;
SG_MUL_VAL_ 1036 P03_VIN_CHARACTER16_B4_RAW MULTIPLEX_PAGE 3-3;
SG_MUL_VAL_ 1036 P04_VARIANTCONFIGBYTE4_B4_RAW MULTIPLEX_PAGE 4-4;
SG_MUL_VAL_ 1036 P05_RELATIVETHROTTLEPOSITION_B4_ MULTIPLEX_PAGE 5-5;
SG_MUL_VAL_ 1036 P06_MANIFOLDABSOLUTEPRESSURE_B4_ MULTIPLEX_PAGE 6-6;
SG_MUL_VAL_ 1036 P07_CONTROL_MODULE_VOLTAGE_DECIV MULTIPLEX_PAGE 7-7;
SG_MUL_VAL_ 1036 P08_TH_2 MULTIPLEX_PAGE 8-8;
SG_MUL_VAL_ 1036 P09_LEARNEDBASELINEB_RAW_UNRESOL MULTIPLEX_PAGE 9-9;
SG_MUL_VAL_ 1036 P0C_SVO2_B2 MULTIPLEX_PAGE 12-12;
SG_MUL_VAL_ 1036 P0D_AFM MULTIPLEX_PAGE 13-13;
SG_MUL_VAL_ 1036 P0E_RUNTIMESINCEENGINESTART MULTIPLEX_PAGE 14-14;
SG_MUL_VAL_ 1036 P0F_ZERO_BYTE_B4_RAW MULTIPLEX_PAGE 15-15;
SG_MUL_VAL_ 1036 P00_ZERO_BYTE_B5_RAW MULTIPLEX_PAGE 0-0;
SG_MUL_VAL_ 1036 P01_VIN_CHARACTER5_B5_RAW MULTIPLEX_PAGE 1-1;
SG_MUL_VAL_ 1036 P02_VIN_CHARACTER11_B5_RAW MULTIPLEX_PAGE 2-2;
SG_MUL_VAL_ 1036 P03_VIN_CHARACTER17_B5_RAW MULTIPLEX_PAGE 3-3;
SG_MUL_VAL_ 1036 P04_VARIANTCONFIGBYTE5_B5_RAW MULTIPLEX_PAGE 4-4;
SG_MUL_VAL_ 1036 P05_ECT_SENSOR_VOLTAGE_B5_RAW MULTIPLEX_PAGE 5-5;
SG_MUL_VAL_ 1036 P06_BARO_SENSOR_VOLTAGE_B5_RAW MULTIPLEX_PAGE 6-6;
SG_MUL_VAL_ 1036 P07_APP_SENSOR_A_VOLTAGE_B5_RAW MULTIPLEX_PAGE 7-7;
SG_MUL_VAL_ 1036 P08_RELTHW MULTIPLEX_PAGE 8-8;
SG_MUL_VAL_ 1036 P09_THICMD MULTIPLEX_PAGE 9-9;
SG_MUL_VAL_ 1036 P0A_SHORTTERMFUELTRIMBANK1_B5_RA MULTIPLEX_PAGE 10-10;
SG_MUL_VAL_ 1036 P0B_LAMBDA_B2 MULTIPLEX_PAGE 11-11;
SG_MUL_VAL_ 1036 P0C_TOUT MULTIPLEX_PAGE 12-12;
SG_MUL_VAL_ 1036 P0D_ZERO_BYTE_B5_RAW MULTIPLEX_PAGE 13-13;
SG_MUL_VAL_ 1036 P0F_ZERO_BYTE_B5_RAW MULTIPLEX_PAGE 15-15;
SG_MUL_VAL_ 1036 P00_ZERO_BYTE_B6_RAW MULTIPLEX_PAGE 0-0;
SG_MUL_VAL_ 1036 P01_VIN_CHARACTER6_B6_RAW MULTIPLEX_PAGE 1-1;
SG_MUL_VAL_ 1036 P02_VIN_CHARACTER12_B6_RAW MULTIPLEX_PAGE 2-2;
SG_MUL_VAL_ 1036 P03_IDENTIFICATIONEXTRABYTE_RAW_ MULTIPLEX_PAGE 3-3;
SG_MUL_VAL_ 1036 P04_ZERO_BYTE_B6_RAW MULTIPLEX_PAGE 4-4;
SG_MUL_VAL_ 1036 P05_ENGINECOOLANTTEMPERATURE_B6_ MULTIPLEX_PAGE 5-5;
SG_MUL_VAL_ 1036 P06_BAROMETRICPRESSURE_B6_RAW MULTIPLEX_PAGE 6-6;
SG_MUL_VAL_ 1036 P07_APP_SENSOR_B_VOLTAGE_B6_RAW MULTIPLEX_PAGE 7-7;
SG_MUL_VAL_ 1036 P0A_LONGTERMFUELTRIMBANK1_B6_RAW MULTIPLEX_PAGE 10-10;
SG_MUL_VAL_ 1036 P0D_ZERO_BYTE_B6_RAW MULTIPLEX_PAGE 13-13;
SG_MUL_VAL_ 1036 P0E_COMMANDEDEVAPORATIVEPURGE_B6 MULTIPLEX_PAGE 14-14;
SG_MUL_VAL_ 1036 P0F_ZERO_BYTE_B6_RAW MULTIPLEX_PAGE 15-15;
SG_MUL_VAL_ 1039 P00_PAGE0_FORMAT_RAW MULTIPLEX_PAGE 0-0;
SG_MUL_VAL_ 1039 P01_CONFIG_BYTE1_RAW MULTIPLEX_PAGE 1-1;
SG_MUL_VAL_ 1039 P02_NEW MULTIPLEX_PAGE 2-2;
SG_MUL_VAL_ 1039 P03_TW MULTIPLEX_PAGE 3-3;
SG_MUL_VAL_ 1039 P04_PAAD MULTIPLEX_PAGE 4-4;
SG_MUL_VAL_ 1039 P05_NMW MULTIPLEX_PAGE 5-5;
SG_MUL_VAL_ 1039 P06_IACTA MULTIPLEX_PAGE 6-6;
SG_MUL_VAL_ 1039 P07_PLA MULTIPLEX_PAGE 7-7;
SG_MUL_VAL_ 1039 UnspecifiedPage_rsvd0 MULTIPLEX_PAGE 8-15;
SG_MUL_VAL_ 1039 P07_SHG MULTIPLEX_PAGE 7-7;
SG_MUL_VAL_ 1039 P07_SHF MULTIPLEX_PAGE 7-7;
SG_MUL_VAL_ 1039 P07_SHE MULTIPLEX_PAGE 7-7;
SG_MUL_VAL_ 1039 P07_SHD MULTIPLEX_PAGE 7-7;
SG_MUL_VAL_ 1039 P07_SHC MULTIPLEX_PAGE 7-7;
SG_MUL_VAL_ 1039 P07_SHB MULTIPLEX_PAGE 7-7;
SG_MUL_VAL_ 1039 P07_SHA MULTIPLEX_PAGE 7-7;
SG_MUL_VAL_ 1039 P00_PAGE0_EVENT_RAW MULTIPLEX_PAGE 0-0;
SG_MUL_VAL_ 1039 P01_CONFIG_BYTE2_RAW MULTIPLEX_PAGE 1-1;
SG_MUL_VAL_ 1039 P02_VNC MULTIPLEX_PAGE 2-2;
SG_MUL_VAL_ 1039 P03_VB MULTIPLEX_PAGE 3-3;
SG_MUL_VAL_ 1039 P04_PA MULTIPLEX_PAGE 4-4;
SG_MUL_VAL_ 1039 P06_ICMDB MULTIPLEX_PAGE 6-6;
SG_MUL_VAL_ 1039 P07_TATFAD MULTIPLEX_PAGE 7-7;
SG_MUL_VAL_ 1039 UnspecifiedPage_rsvd1 MULTIPLEX_PAGE 8-15;
SG_MUL_VAL_ 1039 P01_CONFIG_BYTE3_RAW MULTIPLEX_PAGE 1-1;
SG_MUL_VAL_ 1039 P02_VNM MULTIPLEX_PAGE 2-2;
SG_MUL_VAL_ 1039 P03_SO MULTIPLEX_PAGE 3-3;
SG_MUL_VAL_ 1039 P04_NEW MULTIPLEX_PAGE 4-4;
SG_MUL_VAL_ 1039 P05_APSAT MULTIPLEX_PAGE 5-5;
SG_MUL_VAL_ 1039 P06_IACTB MULTIPLEX_PAGE 6-6;
SG_MUL_VAL_ 1039 P07_TATF MULTIPLEX_PAGE 7-7;
SG_MUL_VAL_ 1039 UnspecifiedPage_rsvd2 MULTIPLEX_PAGE 8-15;
SG_MUL_VAL_ 1039 P00_PAGE0_LENGTH_RAW MULTIPLEX_PAGE 0-0;
SG_MUL_VAL_ 1039 P01_CONFIG_BYTE4_RAW MULTIPLEX_PAGE 1-1;
SG_MUL_VAL_ 1039 P02_THAD1 MULTIPLEX_PAGE 2-2;
SG_MUL_VAL_ 1039 P03_STATUS_RAW MULTIPLEX_PAGE 3-3;
SG_MUL_VAL_ 1039 P05_APS1AD MULTIPLEX_PAGE 5-5;
SG_MUL_VAL_ 1039 P06_ICMDC MULTIPLEX_PAGE 6-6;
SG_MUL_VAL_ 1039 P07_IACTD MULTIPLEX_PAGE 7-7;
SG_MUL_VAL_ 1039 UnspecifiedPage_rsvd3 MULTIPLEX_PAGE 8-15;
SG_MUL_VAL_ 1039 P00_PAGE0_RESERVED_RAW MULTIPLEX_PAGE 0-0;
SG_MUL_VAL_ 1039 P01_CONFIG_BYTE5_RAW MULTIPLEX_PAGE 1-1;
SG_MUL_VAL_ 1039 P02_RELTH MULTIPLEX_PAGE 2-2;
SG_MUL_VAL_ 1039 P03_PBAD MULTIPLEX_PAGE 3-3;
SG_MUL_VAL_ 1039 P04_NCW MULTIPLEX_PAGE 4-4;
SG_MUL_VAL_ 1039 P05_APS2AD MULTIPLEX_PAGE 5-5;
SG_MUL_VAL_ 1039 P06_IACTC MULTIPLEX_PAGE 6-6;
SG_MUL_VAL_ 1039 P07_ICMDD MULTIPLEX_PAGE 7-7;
SG_MUL_VAL_ 1039 UnspecifiedPage_rsvd4 MULTIPLEX_PAGE 8-15;
SG_MUL_VAL_ 1039 P01_CONFIG_BYTE6_RAW MULTIPLEX_PAGE 1-1;
SG_MUL_VAL_ 1039 P02_TWAD MULTIPLEX_PAGE 2-2;
SG_MUL_VAL_ 1039 P03_PB MULTIPLEX_PAGE 3-3;
SG_MUL_VAL_ 1039 P05_ICMDA MULTIPLEX_PAGE 5-5;
SG_MUL_VAL_ 1039 P06_VSP MULTIPLEX_PAGE 6-6;
SG_MUL_VAL_ 1039 P07_OPPLSW MULTIPLEX_PAGE 7-7;
SG_MUL_VAL_ 1039 UnspecifiedPage_rsvd5 MULTIPLEX_PAGE 8-15;
SG_MUL_VAL_ 1039 P07_OPSWB MULTIPLEX_PAGE 7-7;
SG_MUL_VAL_ 1039 P07_OPSWA MULTIPLEX_PAGE 7-7;
SG_MUL_VAL_ 1039 P07_OP6SW MULTIPLEX_PAGE 7-7;
SG_MUL_VAL_ 1039 P07_OP5SW MULTIPLEX_PAGE 7-7;
SG_MUL_VAL_ 1039 P07_OP4SW MULTIPLEX_PAGE 7-7;
SG_MUL_VAL_ 1039 P07_OP3SW MULTIPLEX_PAGE 7-7;
SG_MUL_VAL_ 1039 P07_OP2SW MULTIPLEX_PAGE 7-7;
SG_MUL_VAL_ 1088 P31_unknown0 Mux 49-49;
SG_MUL_VAL_ 1088 P32_RCLPBAT Mux 50-50;
SG_MUL_VAL_ 1088 P33_unknown0 Mux 51-51;
SG_MUL_VAL_ 1088 P39_unknown0 Mux 57-57;
SG_MUL_VAL_ 1088 P3A_page3A_temp_word_RAW Mux 58-58;
SG_MUL_VAL_ 1088 UnspecifiedPage_unknown0 Mux 0-48, 52-56, 59-255;
SG_MUL_VAL_ 1088 P31_unknown1 Mux 49-49;
SG_MUL_VAL_ 1088 P33_unknown1 Mux 51-51;
SG_MUL_VAL_ 1088 P39_unknown1 Mux 57-57;
SG_MUL_VAL_ 1088 P3A_unknown0 Mux 58-58;
SG_MUL_VAL_ 1088 UnspecifiedPage_unknown1 Mux 0-48, 52-56, 59-255;
SG_MUL_VAL_ 1088 P31_TPBAT Mux 49-49;
SG_MUL_VAL_ 1088 P32_raw34 Mux 50-50;
SG_MUL_VAL_ 1088 P33_unknown2 Mux 51-51;
SG_MUL_VAL_ 1088 P39_VBATCO Mux 57-57;
SG_MUL_VAL_ 1088 P3A_page3A_word34 Mux 58-58;
SG_MUL_VAL_ 1088 UnspecifiedPage_unknown2 Mux 0-48, 52-56, 59-255;
SG_MUL_VAL_ 1088 P31_SOCPBAT Mux 49-49;
SG_MUL_VAL_ 1088 P33_unknown3 Mux 51-51;
SG_MUL_VAL_ 1088 P39_SOHQPBAT Mux 57-57;
SG_MUL_VAL_ 1088 UnspecifiedPage_unknown3 Mux 0-48, 52-56, 59-255;
SG_MUL_VAL_ 1088 P31_d5_low3 Mux 49-49;
SG_MUL_VAL_ 1088 P32_raw56 Mux 50-50;
SG_MUL_VAL_ 1088 P33_unknown4 Mux 51-51;
SG_MUL_VAL_ 1088 P39_SOFVPBAT Mux 57-57;
SG_MUL_VAL_ 1088 P3A_unknown1 Mux 58-58;
SG_MUL_VAL_ 1088 UnspecifiedPage_unknown4 Mux 0-48, 52-56, 59-255;
SG_MUL_VAL_ 1088 P31_d5_mid2 Mux 49-49;
SG_MUL_VAL_ 1088 P31_d5_bit5 Mux 49-49;
SG_MUL_VAL_ 1088 P31_d5_bit6 Mux 49-49;
SG_MUL_VAL_ 1088 P31_unknown2 Mux 49-49;
SG_MUL_VAL_ 1088 P31_d6_low3 Mux 49-49;
SG_MUL_VAL_ 1088 P33_unknown5 Mux 51-51;
SG_MUL_VAL_ 1088 P39_BATSRST Mux 57-57;
SG_MUL_VAL_ 1088 P3A_unknown2 Mux 58-58;
SG_MUL_VAL_ 1088 UnspecifiedPage_unknown5 Mux 0-48, 52-56, 59-255;
SG_MUL_VAL_ 1088 P39_BDCHGBAT Mux 57-57;
SG_MUL_VAL_ 1088 P39_d6_bit2 Mux 57-57;
SG_MUL_VAL_ 1088 P31_unknown3 Mux 49-49;
SG_MUL_VAL_ 1088 P39_d6_bit3 Mux 57-57;
SG_MUL_VAL_ 1088 P39_unknown2 Mux 57-57;
SG_MUL_VAL_ 1088 P31_d6_bit6 Mux 49-49;
SG_MUL_VAL_ 1088 P31_d6_bit7 Mux 49-49;
SG_MUL_VAL_ 1088 P39_d6_bit7 Mux 57-57;
